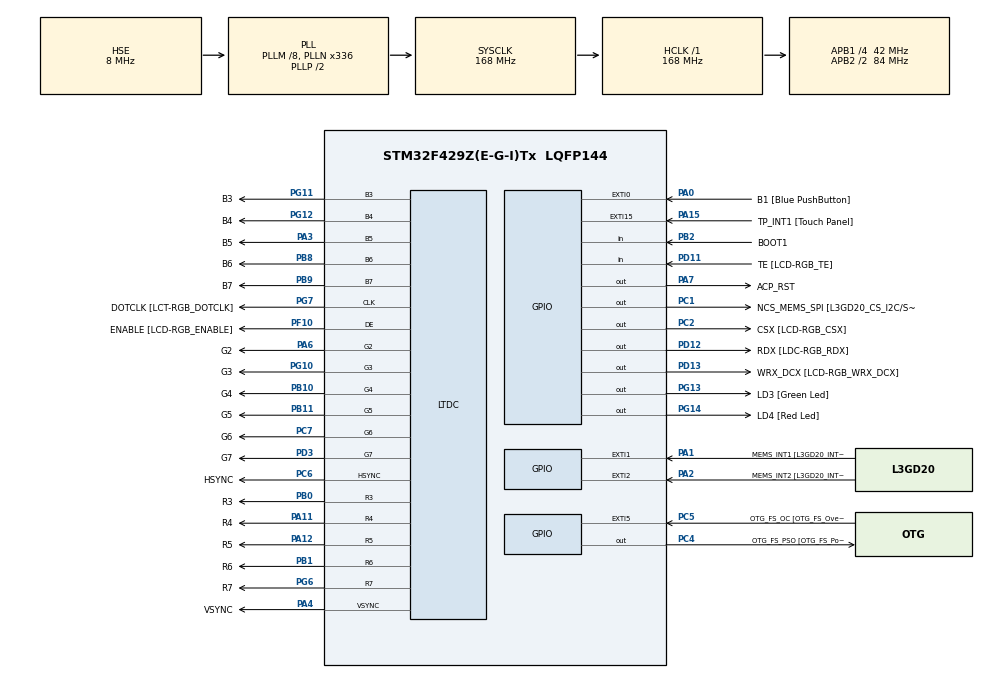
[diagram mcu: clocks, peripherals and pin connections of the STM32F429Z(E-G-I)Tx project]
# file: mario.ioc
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FREERTOS.Tasks01=defaultTask,0,128,StartDefaultTask
Mcu.Family=STM32F4
Mcu.Name=STM32F429Z(E-G-I)Tx
Mcu.Package=LQFP144
NVIC.PriorityGroup=NVIC_PRIORITYGROUP_4
NVIC.TIM6_DAC_IRQn=true\:5\:0\:false
PA0/WKUP.GPIO_Label=B1 [Blue PushButton]
PA0/WKUP.GPIO_ModeDefaultEXTI=GPIO_MODE_EVT_RISING
PA0/WKUP.GPIO_PuPd=GPIO_NOPULL
PA0/WKUP.Signal=GPXTI0
PA1.GPIO_Label=MEMS_INT1 [L3GD20_INT1]
PA1.GPIO_ModeDefaultEXTI=GPIO_MODE_EVT_RISING
PA1.GPIO_PuPd=GPIO_NOPULL
PA1.Signal=GPXTI1
PA11.GPIO_Label=R4
PA11.GPIO_Mode=GPIO_MODE_AF_PP
PA11.GPIO_PuPd=GPIO_NOPULL
PA11.GPIO_Speed=GPIO_SPEED_LOW
PA11.Mode=RGB565
PA11.Signal=LTDC_R4
PA12.GPIO_Label=R5
PA12.GPIO_Mode=GPIO_MODE_AF_PP
PA12.GPIO_PuPd=GPIO_NOPULL
PA12.GPIO_Speed=GPIO_SPEED_LOW
PA12.Mode=RGB565
PA12.Signal=LTDC_R5
PA13.GPIO_Label=SWDIO
PA13.Mode=Serial-Wire
PA13.Signal=SYS_JTMS-SWDIO
PA14.GPIO_Label=SWCLK
PA14.Mode=Serial-Wire
PA14.Signal=SYS_JTCK-SWCLK
PA15.GPIO_Label=TP_INT1 [Touch Panel]
PA15.GPIO_ModeDefaultEXTI=GPIO_MODE_EVT_RISING
PA15.GPIO_PuPd=GPIO_NOPULL
PA15.Signal=GPXTI15
PA2.GPIO_Label=MEMS_INT2 [L3GD20_INT2]
PA2.GPIO_ModeDefaultEXTI=GPIO_MODE_EVT_RISING
PA2.GPIO_PuPd=GPIO_NOPULL
PA2.Signal=GPXTI2
PA3.GPIO_Label=B5
PA3.GPIO_Mode=GPIO_MODE_AF_PP
PA3.GPIO_PuPd=GPIO_NOPULL
PA3.GPIO_Speed=GPIO_SPEED_LOW
PA3.Mode=RGB565
PA3.Signal=LTDC_B5
PA4.GPIO_Label=VSYNC
PA4.GPIO_Mode=GPIO_MODE_AF_PP
PA4.GPIO_PuPd=GPIO_NOPULL
PA4.GPIO_Speed=GPIO_SPEED_LOW
PA4.Mode=RGB565
PA4.Signal=LTDC_VSYNC
PA6.GPIO_Label=G2
PA6.GPIO_Mode=GPIO_MODE_AF_PP
PA6.GPIO_PuPd=GPIO_NOPULL
PA6.GPIO_Speed=GPIO_SPEED_LOW
PA6.Mode=RGB565
PA6.Signal=LTDC_G2
PA7.GPIO_Label=ACP_RST
PA7.GPIO_Mode=GPIO_MODE_OUTPUT_PP
PA7.GPIO_PuPd=GPIO_NOPULL
PA7.GPIO_Speed=GPIO_SPEED_LOW
PA7.Signal=GPIO_Output
PA8.GPIO_Label=I2C3_SCL [ACP/RF_SCL]
PA8.GPIO_Mode=GPIO_MODE_AF_OD
PA8.GPIO_PuPd=GPIO_NOPULL
PA8.GPIO_Speed=GPIO_SPEED_LOW
PA8.Signal=I2C3_SCL
PB0.GPIO_Label=R3
PB0.GPIO_Mode=GPIO_MODE_AF_PP
PB0.GPIO_PuPd=GPIO_NOPULL
PB0.GPIO_Speed=GPIO_SPEED_LOW
PB0.Mode=RGB565
PB0.Signal=LTDC_R3
PB1.GPIO_Label=R6
PB1.GPIO_Mode=GPIO_MODE_AF_PP
PB1.GPIO_PuPd=GPIO_NOPULL
PB1.GPIO_Speed=GPIO_SPEED_LOW
PB1.Mode=RGB565
PB1.Signal=LTDC_R6
PB10.GPIO_Label=G4
PB10.GPIO_Mode=GPIO_MODE_AF_PP
PB10.GPIO_PuPd=GPIO_NOPULL
PB10.GPIO_Speed=GPIO_SPEED_LOW
PB10.Mode=RGB565
PB10.Signal=LTDC_G4
PB11.GPIO_Label=G5
PB11.GPIO_Mode=GPIO_MODE_AF_PP
PB11.GPIO_PuPd=GPIO_NOPULL
PB11.GPIO_Speed=GPIO_SPEED_LOW
PB11.Mode=RGB565
PB11.Signal=LTDC_G5
PB12.GPIO_Label=OTG_FS_ID
PB12.GPIO_Mode=GPIO_MODE_AF_PP
PB12.GPIO_PuPd=GPIO_NOPULL
PB12.GPIO_Speed=GPIO_SPEED_LOW
PB12.Signal=USB_OTG_HS_ID
PB13.GPIO_Label=VBUS_FS
PB13.GPIO_Mode=GPIO_MODE_INPUT
PB13.GPIO_PuPd=GPIO_NOPULL
PB13.Signal=USB_OTG_HS_VBUS
PB14.GPIO_Label=OTG_FS_DM
PB14.GPIO_Mode=GPIO_MODE_AF_PP
PB14.GPIO_PuPd=GPIO_NOPULL
PB14.GPIO_Speed=GPIO_SPEED_LOW
PB14.Signal=USB_OTG_HS_DM
PB15.GPIO_Label=OTG_FS_DP
PB15.GPIO_Mode=GPIO_MODE_AF_PP
PB15.GPIO_PuPd=GPIO_NOPULL
PB15.GPIO_Speed=GPIO_SPEED_LOW
PB15.Signal=USB_OTG_HS_DP
PB2/BOOT1.GPIO_Label=BOOT1
PB2/BOOT1.GPIO_Mode=GPIO_MODE_INPUT
PB2/BOOT1.GPIO_PuPd=GPIO_NOPULL
PB2/BOOT1.Signal=GPIO_Input
PB5.GPIO_Label=SDCKE1
PB5.GPIO_Mode=GPIO_MODE_AF_PP
PB5.GPIO_PuPd=GPIO_NOPULL
PB5.GPIO_Speed=GPIO_SPEED_HIGH
PB5.Signal=FMC_SDCKE1
PB6.GPIO_Label=SDNE1 [SDRAM_CS]
PB6.GPIO_Mode=GPIO_MODE_AF_PP
PB6.GPIO_PuPd=GPIO_NOPULL
PB6.GPIO_Speed=GPIO_SPEED_HIGH
PB6.Signal=FMC_SDNE1
PB8.GPIO_Label=B6
PB8.GPIO_Mode=GPIO_MODE_AF_PP
PB8.GPIO_PuPd=GPIO_NOPULL
PB8.GPIO_Speed=GPIO_SPEED_LOW
PB8.Mode=RGB565
PB8.Signal=LTDC_B6
PB9.GPIO_Label=B7
PB9.GPIO_Mode=GPIO_MODE_AF_PP
PB9.GPIO_PuPd=GPIO_NOPULL
PB9.GPIO_Speed=GPIO_SPEED_LOW
PB9.Mode=RGB565
PB9.Signal=LTDC_B7
PC0.GPIO_Label=SDNWE
PC0.GPIO_Mode=GPIO_MODE_AF_PP
PC0.GPIO_PuPd=GPIO_NOPULL
PC0.GPIO_Speed=GPIO_SPEED_HIGH
PC0.Signal=FMC_SDNWE
PC1.GPIO_Label=NCS_MEMS_SPI [L3GD20_CS_I2C/SPI]
PC1.GPIO_Mode=GPIO_MODE_OUTPUT_PP
PC1.GPIO_PuPd=GPIO_NOPULL
PC1.GPIO_Speed=GPIO_SPEED_LOW
PC1.Signal=GPIO_Output
PC10.GPIO_Label=R2
PC10.GPIO_Mode=GPIO_MODE_AF_PP
PC10.GPIO_PuPd=GPIO_NOPULL
PC10.GPIO_Speed=GPIO_SPEED_LOW
PC10.Signal=LTDC_R2
PC14/OSC32_IN.GPIO_Label=PC14-OSC32_IN
PC14/OSC32_IN.Signal=RCC_OSC32_IN
PC15/OSC32_OUT.GPIO_Label=PC15-OSC32_OUT
PC15/OSC32_OUT.Signal=RCC_OSC32_OUT
PC2.GPIO_Label=CSX [LCD-RGB_CSX]
PC2.GPIO_Mode=GPIO_MODE_OUTPUT_PP
PC2.GPIO_PuPd=GPIO_NOPULL
PC2.GPIO_Speed=GPIO_SPEED_LOW
PC2.Signal=GPIO_Output
PC4.GPIO_Label=OTG_FS_PSO [OTG_FS_PowerSwitchOn]
PC4.GPIO_Mode=GPIO_MODE_OUTPUT_PP
PC4.GPIO_PuPd=GPIO_NOPULL
PC4.GPIO_Speed=GPIO_SPEED_LOW
PC4.Signal=GPIO_Output
PC5.GPIO_Label=OTG_FS_OC [OTG_FS_OverCurrent]
PC5.Signal=GPXTI5
PC6.GPIO_Label=HSYNC
PC6.GPIO_Mode=GPIO_MODE_AF_PP
PC6.GPIO_PuPd=GPIO_NOPULL
PC6.GPIO_Speed=GPIO_SPEED_LOW
PC6.Mode=RGB565
PC6.Signal=LTDC_HSYNC
PC7.GPIO_Label=G6
PC7.GPIO_Mode=GPIO_MODE_AF_PP
PC7.GPIO_PuPd=GPIO_NOPULL
PC7.GPIO_Speed=GPIO_SPEED_LOW
PC7.Mode=RGB565
PC7.Signal=LTDC_G6
PC9.GPIO_Label=I2C3_SDA [ACP/RF_SDA]
PC9.GPIO_Mode=GPIO_MODE_AF_OD
PC9.GPIO_PuPd=GPIO_NOPULL
PC9.GPIO_Speed=GPIO_SPEED_LOW
PC9.Signal=I2C3_SDA
PD0.GPIO_Label=D2
PD0.GPIO_Mode=GPIO_MODE_AF_PP
PD0.GPIO_PuPd=GPIO_NOPULL
PD0.GPIO_Speed=GPIO_SPEED_HIGH
PD0.Signal=FMC_D2_DA2
PD1.GPIO_Label=D3
PD1.GPIO_Mode=GPIO_MODE_AF_PP
PD1.GPIO_PuPd=GPIO_NOPULL
PD1.GPIO_Speed=GPIO_SPEED_HIGH
PD1.Signal=FMC_D3_DA3
PD10.GPIO_Label=D15
PD10.GPIO_Mode=GPIO_MODE_AF_PP
PD10.GPIO_PuPd=GPIO_NOPULL
PD10.GPIO_Speed=GPIO_SPEED_HIGH
PD10.Signal=FMC_D15_DA15
PD11.GPIO_Label=TE [LCD-RGB_TE]
PD11.GPIO_Mode=GPIO_MODE_INPUT
PD11.GPIO_PuPd=GPIO_NOPULL
PD11.Signal=GPIO_Input
PD12.GPIO_Label=RDX [LDC-RGB_RDX]
PD12.GPIO_Mode=GPIO_MODE_OUTPUT_PP
PD12.GPIO_PuPd=GPIO_NOPULL
PD12.GPIO_Speed=GPIO_SPEED_LOW
PD12.Signal=GPIO_Output
PD13.GPIO_Label=WRX_DCX [LCD-RGB_WRX_DCX]
PD13.GPIO_Mode=GPIO_MODE_OUTPUT_PP
PD13.GPIO_PuPd=GPIO_NOPULL
PD13.GPIO_Speed=GPIO_SPEED_LOW
PD13.Signal=GPIO_Output
PD14.GPIO_Label=D0
PD14.GPIO_Mode=GPIO_MODE_AF_PP
PD14.GPIO_PuPd=GPIO_NOPULL
PD14.GPIO_Speed=GPIO_SPEED_HIGH
PD14.Signal=FMC_D0_DA0
PD15.GPIO_Label=D1
PD15.GPIO_Mode=GPIO_MODE_AF_PP
PD15.GPIO_PuPd=GPIO_NOPULL
PD15.GPIO_Speed=GPIO_SPEED_HIGH
PD15.Signal=FMC_D1_DA1
PD3.GPIO_Label=G7
PD3.GPIO_Mode=GPIO_MODE_AF_PP
PD3.GPIO_PuPd=GPIO_NOPULL
PD3.GPIO_Speed=GPIO_SPEED_LOW
PD3.Mode=RGB565
PD3.Signal=LTDC_G7
PD6.GPIO_Label=B2
PD6.GPIO_Mode=GPIO_MODE_AF_PP
PD6.GPIO_PuPd=GPIO_NOPULL
PD6.GPIO_Speed=GPIO_SPEED_LOW
PD6.Signal=LTDC_B2
PD8.GPIO_Label=D13
PD8.GPIO_Mode=GPIO_MODE_AF_PP
PD8.GPIO_PuPd=GPIO_NOPULL
PD8.GPIO_Speed=GPIO_SPEED_HIGH
PD8.Signal=FMC_D13_DA13
PD9.GPIO_Label=D14
PD9.GPIO_Mode=GPIO_MODE_AF_PP
PD9.GPIO_PuPd=GPIO_NOPULL
PD9.GPIO_Speed=GPIO_SPEED_HIGH
PD9.Signal=FMC_D14_DA14
PE0.GPIO_Label=NBL0 [SDRAM_LDQM]
PE0.GPIO_Mode=GPIO_MODE_AF_PP
PE0.GPIO_PuPd=GPIO_NOPULL
PE0.GPIO_Speed=GPIO_SPEED_HIGH
PE0.Signal=FMC_NBL0
PE1.GPIO_Label=NBL1 [SDRAM_UDQM]
PE1.GPIO_Mode=GPIO_MODE_AF_PP
PE1.GPIO_PuPd=GPIO_NOPULL
PE1.GPIO_Speed=GPIO_SPEED_HIGH
PE1.Signal=FMC_NBL1
PE10.GPIO_Label=D7
PE10.GPIO_Mode=GPIO_MODE_AF_PP
PE10.GPIO_PuPd=GPIO_NOPULL
PE10.GPIO_Speed=GPIO_SPEED_HIGH
PE10.Signal=FMC_D7_DA7
PE11.GPIO_Label=D8
PE11.GPIO_Mode=GPIO_MODE_AF_PP
PE11.GPIO_PuPd=GPIO_NOPULL
PE11.GPIO_Speed=GPIO_SPEED_HIGH
PE11.Signal=FMC_D8_DA8
PE12.GPIO_Label=D9
PE12.GPIO_Mode=GPIO_MODE_AF_PP
PE12.GPIO_PuPd=GPIO_NOPULL
PE12.GPIO_Speed=GPIO_SPEED_HIGH
PE12.Signal=FMC_D9_DA9
PE13.GPIO_Label=D10
PE13.GPIO_Mode=GPIO_MODE_AF_PP
PE13.GPIO_PuPd=GPIO_NOPULL
PE13.GPIO_Speed=GPIO_SPEED_HIGH
PE13.Signal=FMC_D10_DA10
PE14.GPIO_Label=D11
PE14.GPIO_Mode=GPIO_MODE_AF_PP
PE14.GPIO_PuPd=GPIO_NOPULL
PE14.GPIO_Speed=GPIO_SPEED_HIGH
PE14.Signal=FMC_D11_DA11
PE15.GPIO_Label=D12
PE15.GPIO_Mode=GPIO_MODE_AF_PP
PE15.GPIO_PuPd=GPIO_NOPULL
PE15.GPIO_Speed=GPIO_SPEED_HIGH
PE15.Signal=FMC_D12_DA12
PE7.GPIO_Label=D4
PE7.GPIO_Mode=GPIO_MODE_AF_PP
PE7.GPIO_PuPd=GPIO_NOPULL
PE7.GPIO_Speed=GPIO_SPEED_HIGH
PE7.Signal=FMC_D4_DA4
PE8.GPIO_Label=D5
PE8.GPIO_Mode=GPIO_MODE_AF_PP
PE8.GPIO_PuPd=GPIO_NOPULL
PE8.GPIO_Speed=GPIO_SPEED_HIGH
PE8.Signal=FMC_D5_DA5
PE9.GPIO_Label=D6
PE9.GPIO_Mode=GPIO_MODE_AF_PP
PE9.GPIO_PuPd=GPIO_NOPULL
PE9.GPIO_Speed=GPIO_SPEED_HIGH
PE9.Signal=FMC_D6_DA6
PF0.GPIO_Label=A0
PF0.GPIO_Mode=GPIO_MODE_AF_PP
PF0.GPIO_PuPd=GPIO_NOPULL
PF0.GPIO_Speed=GPIO_SPEED_HIGH
PF0.Signal=FMC_A0
PF1.GPIO_Label=A1
PF1.GPIO_Mode=GPIO_MODE_AF_PP
PF1.GPIO_PuPd=GPIO_NOPULL
PF1.GPIO_Speed=GPIO_SPEED_HIGH
PF1.Signal=FMC_A1
PF10.GPIO_Label=ENABLE [LCD-RGB_ENABLE]
PF10.GPIO_Mode=GPIO_MODE_AF_PP
PF10.GPIO_PuPd=GPIO_NOPULL
PF10.GPIO_Speed=GPIO_SPEED_LOW
PF10.Mode=RGB565
PF10.Signal=LTDC_DE
PF11.GPIO_Label=SDNRAS
PF11.GPIO_Mode=GPIO_MODE_AF_PP
PF11.GPIO_PuPd=GPIO_NOPULL
PF11.GPIO_Speed=GPIO_SPEED_HIGH
PF11.Signal=FMC_SDNRAS
PF12.GPIO_Label=A6
PF12.GPIO_Mode=GPIO_MODE_AF_PP
PF12.GPIO_PuPd=GPIO_NOPULL
PF12.GPIO_Speed=GPIO_SPEED_HIGH
PF12.Signal=FMC_A6
PF13.GPIO_Label=A7
PF13.GPIO_Mode=GPIO_MODE_AF_PP
PF13.GPIO_PuPd=GPIO_NOPULL
PF13.GPIO_Speed=GPIO_SPEED_HIGH
PF13.Signal=FMC_A7
PF14.GPIO_Label=A8
PF14.GPIO_Mode=GPIO_MODE_AF_PP
PF14.GPIO_PuPd=GPIO_NOPULL
PF14.GPIO_Speed=GPIO_SPEED_HIGH
PF14.Signal=FMC_A8
PF15.GPIO_Label=A9
PF15.GPIO_Mode=GPIO_MODE_AF_PP
PF15.GPIO_PuPd=GPIO_NOPULL
PF15.GPIO_Speed=GPIO_SPEED_HIGH
PF15.Signal=FMC_A9
PF2.GPIO_Label=A2
PF2.GPIO_Mode=GPIO_MODE_AF_PP
PF2.GPIO_PuPd=GPIO_NOPULL
PF2.GPIO_Speed=GPIO_SPEED_HIGH
PF2.Signal=FMC_A2
PF3.GPIO_Label=A3
PF3.GPIO_Mode=GPIO_MODE_AF_PP
PF3.GPIO_PuPd=GPIO_NOPULL
PF3.GPIO_Speed=GPIO_SPEED_HIGH
PF3.Signal=FMC_A3
PF4.GPIO_Label=A4
PF4.GPIO_Mode=GPIO_MODE_AF_PP
PF4.GPIO_PuPd=GPIO_NOPULL
PF4.GPIO_Speed=GPIO_SPEED_HIGH
PF4.Signal=FMC_A4
PF5.GPIO_Label=A5
PF5.GPIO_Mode=GPIO_MODE_AF_PP
PF5.GPIO_PuPd=GPIO_NOPULL
PF5.GPIO_Speed=GPIO_SPEED_HIGH
PF5.Signal=FMC_A5
PF7.GPIO_Label=SPI5_SCK [L3GD20_SCL/SPC]
PF7.GPIO_Mode=GPIO_MODE_AF_PP
PF7.GPIO_PuPd=GPIO_NOPULL
PF7.GPIO_Speed=GPIO_SPEED_LOW
PF7.Signal=SPI5_SCK
PF8.GPIO_Label=SPI5_MISO [L3GD20_SDO]
PF8.GPIO_Mode=GPIO_MODE_AF_PP
PF8.GPIO_PuPd=GPIO_NOPULL
PF8.GPIO_Speed=GPIO_SPEED_LOW
PF8.Signal=SPI5_MISO
PF9.GPIO_Label=SPI5_MOSI [L3GD20_SDA/SDI/SDO]
PF9.GPIO_Mode=GPIO_MODE_AF_PP
PF9.GPIO_PuPd=GPIO_NOPULL
PF9.GPIO_Speed=GPIO_SPEED_LOW
PF9.Signal=SPI5_MOSI
PG0.GPIO_Label=A10
PG0.GPIO_Mode=GPIO_MODE_AF_PP
PG0.GPIO_PuPd=GPIO_NOPULL
PG0.GPIO_Speed=GPIO_SPEED_HIGH
PG0.Signal=FMC_A10
PG1.GPIO_Label=A11
PG1.GPIO_Mode=GPIO_MODE_AF_PP
PG1.GPIO_PuPd=GPIO_NOPULL
PG1.GPIO_Speed=GPIO_SPEED_HIGH
PG1.Signal=FMC_A11
PG10.GPIO_Label=G3
PG10.GPIO_Mode=GPIO_MODE_AF_PP
PG10.GPIO_PuPd=GPIO_NOPULL
PG10.GPIO_Speed=GPIO_SPEED_LOW
PG10.Mode=RGB565
PG10.Signal=LTDC_G3
PG11.GPIO_Label=B3
PG11.GPIO_Mode=GPIO_MODE_AF_PP
PG11.GPIO_PuPd=GPIO_NOPULL
PG11.GPIO_Speed=GPIO_SPEED_LOW
PG11.Mode=RGB565
PG11.Signal=LTDC_B3
PG12.GPIO_Label=B4
PG12.GPIO_Mode=GPIO_MODE_AF_PP
PG12.GPIO_PuPd=GPIO_NOPULL
PG12.GPIO_Speed=GPIO_SPEED_LOW
PG12.Mode=RGB565
PG12.Signal=LTDC_B4
PG13.GPIO_Label=LD3 [Green Led]
PG13.GPIO_Mode=GPIO_MODE_OUTPUT_PP
PG13.GPIO_PuPd=GPIO_NOPULL
PG13.GPIO_Speed=GPIO_SPEED_LOW
PG13.Signal=GPIO_Output
PG14.GPIO_Label=LD4 [Red Led]
PG14.GPIO_Mode=GPIO_MODE_OUTPUT_PP
PG14.GPIO_PuPd=GPIO_NOPULL
PG14.GPIO_Speed=GPIO_SPEED_LOW
PG14.Signal=GPIO_Output
PG15.GPIO_Label=SDNCAS
PG15.GPIO_Mode=GPIO_MODE_AF_PP
PG15.GPIO_PuPd=GPIO_NOPULL
PG15.GPIO_Speed=GPIO_SPEED_HIGH
PG15.Signal=FMC_SDNCAS
PG4.GPIO_Label=BA0
PG4.GPIO_Mode=GPIO_MODE_AF_PP
PG4.GPIO_PuPd=GPIO_NOPULL
PG4.GPIO_Speed=GPIO_SPEED_HIGH
PG4.Signal=FMC_A14_BA0
PG5.GPIO_Label=BA1
PG5.GPIO_Mode=GPIO_MODE_AF_PP
PG5.GPIO_PuPd=GPIO_NOPULL
PG5.GPIO_Speed=GPIO_SPEED_HIGH
PG5.Signal=FMC_A15_BA1
PG6.GPIO_Label=R7
PG6.GPIO_Mode=GPIO_MODE_AF_PP
PG6.GPIO_PuPd=GPIO_NOPULL
PG6.GPIO_Speed=GPIO_SPEED_LOW
PG6.Mode=RGB565
PG6.Signal=LTDC_R7
PG7.GPIO_Label=DOTCLK [LCT-RGB_DOTCLK]
PG7.GPIO_Mode=GPIO_MODE_AF_PP
PG7.GPIO_PuPd=GPIO_NOPULL
PG7.GPIO_Speed=GPIO_SPEED_LOW
PG7.Mode=RGB565
PG7.Signal=LTDC_CLK
PG8.GPIO_Label=SDCLK
PG8.GPIO_Mode=GPIO_MODE_AF_PP
PG8.GPIO_PuPd=GPIO_NOPULL
PG8.GPIO_Speed=GPIO_SPEED_HIGH
PG8.Signal=FMC_SDCLK
PH0/OSC_IN.GPIO_Label=PH0-OSC_IN
PH0/OSC_IN.Mode=HSE-External-Oscillator
PH0/OSC_IN.Signal=RCC_OSC_IN
PH1/OSC_OUT.GPIO_Label=PH1-OSC_OUT
PH1/OSC_OUT.Mode=HSE-External-Oscillator
PH1/OSC_OUT.Signal=RCC_OSC_OUT
ProjectManager.TargetToolchain=MDK-ARM V4
RCC.48MHZClocksFreq_Value=48000000
RCC.AHBFreq_Value=168000000
RCC.APB1CLKDivider=RCC_HCLK_DIV4
RCC.APB1Freq_Value=42000000
RCC.APB1TimFreq_Value=84000000
RCC.APB2CLKDivider=RCC_HCLK_DIV2
RCC.APB2Freq_Value=84000000
RCC.APB2TimFreq_Value=168000000
RCC.CortexFreq_Value=21000000
RCC.HCLKFreq_Value=168000000
RCC.HSE_VALUE=8000000
RCC.HSI_VALUE=16000000
RCC.LSE_VALUE=32768
RCC.PLLM=8
RCC.PLLN=336
RCC.PLLQ=7
RCC.PLLSAIN=432
RCC.PLLSource=RCC_PLLSOURCE_HSE
RCC.PLLSourceVirtual=RCC_PLLSOURCE_HSE
RCC.SYSCLKFreq_VALUE=168000000
RCC.SYSCLKSource=RCC_SYSCLKSOURCE_PLLCLK
RCC.VCOOutputFreq_Value=336000000
SH.FMC_A0.0=FMC_A0
SH.FMC_A1.0=FMC_A1
SH.FMC_A10.0=FMC_A10
SH.FMC_A11.0=FMC_A11
SH.FMC_A14_BA0.0=FMC_BA0
SH.FMC_A15_BA1.0=FMC_BA1
SH.FMC_A2.0=FMC_A2
SH.FMC_A3.0=FMC_A3
SH.FMC_A4.0=FMC_A4
SH.FMC_A5.0=FMC_A5
SH.FMC_A6.0=FMC_A6
SH.FMC_A7.0=FMC_A7
SH.FMC_A8.0=FMC_A8
SH.FMC_A9.0=FMC_A9
SH.FMC_D0_DA0.0=FMC_D0
SH.FMC_D10_DA10.0=FMC_D10
SH.FMC_D11_DA11.0=FMC_D11
SH.FMC_D12_DA12.0=FMC_D12
SH.FMC_D13_DA13.0=FMC_D13
SH.FMC_D14_DA14.0=FMC_D14
SH.FMC_D15_DA15.0=FMC_D15
SH.FMC_D1_DA1.0=FMC_D1
SH.FMC_D2_DA2.0=FMC_D2
SH.FMC_D3_DA3.0=FMC_D3
SH.FMC_D4_DA4.0=FMC_D4
SH.FMC_D5_DA5.0=FMC_D5
SH.FMC_D6_DA6.0=FMC_D6
SH.FMC_D7_DA7.0=FMC_D7
SH.FMC_D8_DA8.0=FMC_D8
SH.FMC_D9_DA9.0=FMC_D9
SH.FMC_NBL0.0=FMC_NBL0
SH.FMC_NBL1.0=FMC_NBL1
SH.FMC_SDCLK.0=FMC_SDCLK
SH.FMC_SDNCAS.0=FMC_SDNCAS
SH.FMC_SDNRAS.0=FMC_SDNRAS
SH.FMC_SDNWE.0=FMC_SDNWE
TIM6.Period=1000
VP_FREERTOS_VS_ENABLE.Mode=Enabled
VP_TIM6_VS_ClockSourceINT.Mode=Enable_Timer
VP_TIM7_VS_ClockSourceINT.Mode=Enable_Timer
VP_WWDG_VS_WWDG.Mode=WWDG_Activate

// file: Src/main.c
/**
  ******************************************************************************
  * File Name          : main.c
  * Date               : 19/05/2015 23:04:15
  * Description        : Main program body
  ******************************************************************************
  *
  * COPYRIGHT(c) 2015 STMicroelectronics
  *
  * Redistribution and use in source and binary forms, with or without modification,
  * are permitted provided that the following conditions are met:
  *   1. Redistributions of source code must retain the above copyright notice,
  *      this list of conditions and the following disclaimer.
  *   2. Redistributions in binary form must reproduce the above copyright notice,
  *      this list of conditions and the following disclaimer in the documentation
  *      and/or other materials provided with the distribution.
  *   3. Neither the name of STMicroelectronics nor the names of its contributors
  *      may be used to endorse or promote products derived from this software
  *      without specific prior written permission.
  *
  * THIS SOFTWARE IS PROVIDED BY THE COPYRIGHT HOLDERS AND CONTRIBUTORS "AS IS"
  * AND ANY EXPRESS OR IMPLIED WARRANTIES, INCLUDING, BUT NOT LIMITED TO, THE
  * IMPLIED WARRANTIES OF MERCHANTABILITY AND FITNESS FOR A PARTICULAR PURPOSE ARE
  * DISCLAIMED. IN NO EVENT SHALL THE COPYRIGHT HOLDER OR CONTRIBUTORS BE LIABLE
  * FOR ANY DIRECT, INDIRECT, INCIDENTAL, SPECIAL, EXEMPLARY, OR CONSEQUENTIAL
  * DAMAGES (INCLUDING, BUT NOT LIMITED TO, PROCUREMENT OF SUBSTITUTE GOODS OR
  * SERVICES; LOSS OF USE, DATA, OR PROFITS; OR BUSINESS INTERRUPTION) HOWEVER
  * CAUSED AND ON ANY THEORY OF LIABILITY, WHETHER IN CONTRACT, STRICT LIABILITY,
  * OR TORT (INCLUDING NEGLIGENCE OR OTHERWISE) ARISING IN ANY WAY OUT OF THE USE
  * OF THIS SOFTWARE, EVEN IF ADVISED OF THE POSSIBILITY OF SUCH DAMAGE.
  *
  ******************************************************************************
  */

#include "stm32f4xx_hal.h"
#include "cmsis_os.h"
#include "stm32f429i_discovery.h"
#include "..\Components\ili9341\ili9341.h"
#include "..\Components\stmpe811\stmpe811.h"
#include "stm32f429i_discovery_ts.h"
#include "stm32f429i_discovery_io.h"
#include "stm32f429i_discovery_lcd.h"
#include "stm32f429i_discovery_gyroscope.h"
#include "stm32f429i_discovery_sdram.h"
#include "arm_math.h"

typedef struct pos{
	int X;
	int Y;
} pos_t;

static unsigned short map[] = {
  1,1,1,1,1,1,1,1,1,1,1,1,1,1,1,1,1,1,1,
	1,0,0,0,0,0,0,0,0,1,0,0,0,0,0,0,0,0,1,
	1,0,1,1,0,1,1,1,0,1,0,1,1,1,0,1,1,0,1,
	1,0,0,0,0,0,0,0,0,0,0,0,0,0,0,0,0,0,1,
	1,0,1,1,0,1,0,1,1,1,1,1,0,1,0,1,1,0,1,
	1,0,0,0,0,1,0,0,0,1,0,0,0,1,0,0,0,0,1,
	1,1,1,1,0,1,1,1,0,1,0,1,1,1,0,1,1,1,1,
	0,0,0,1,0,1,0,0,0,0,0,0,0,1,0,1,0,0,0,
	1,1,1,1,0,1,0,1,1,1,1,1,0,1,0,1,1,1,1,
	1,1,1,1,0,0,0,1,0,0,0,1,0,0,0,1,1,1,1,
	1,1,1,1,0,1,0,1,1,1,1,1,0,1,0,1,1,1,1,
	0,0,0,1,0,1,0,0,0,0,0,0,0,1,0,1,0,0,0,
	1,1,1,1,0,1,0,1,1,1,1,1,0,1,0,1,1,1,1,
	1,0,0,0,0,0,0,0,0,1,0,0,0,0,0,0,0,0,1,
	1,0,1,1,0,1,1,1,0,1,0,1,1,1,0,1,1,0,1,
	1,0,0,1,0,0,0,0,0,0,0,0,0,0,0,1,0,0,1,
	1,1,0,1,0,1,0,1,1,1,1,1,0,1,0,1,0,1,1,
	1,0,0,0,0,1,0,0,0,1,0,0,0,1,0,0,0,0,1,
	1,0,1,1,1,1,1,1,0,1,0,1,1,1,1,1,1,0,1,
	1,0,0,0,0,0,0,0,0,0,0,0,0,0,0,0,0,0,1,
	1,1,1,1,1,1,1,1,1,1,1,1,1,1,1,1,1,1,1
};

static unsigned short food1_base[] = {
  0,0,0,0,0,0,0,0,0,0,0,0,0,0,0,0,0,0,0,
	0,1,1,1,1,1,1,1,1,0,1,1,1,1,1,1,1,1,0,
	0,1,0,0,1,0,0,0,1,0,1,0,0,0,1,0,0,1,0,
	0,1,1,1,1,1,1,1,1,1,1,1,1,1,1,1,1,1,0,
	0,1,0,0,1,0,1,0,0,0,0,0,1,0,1,0,0,1,0,
	0,1,1,1,1,0,1,1,1,0,1,1,1,0,1,1,1,1,0,
	0,0,0,0,1,0,0,0,1,0,1,0,0,0,1,0,0,0,0,
	0,0,0,0,1,0,1,1,1,0,1,1,1,0,1,0,0,0,0,
	0,0,0,0,1,0,1,0,0,0,0,0,1,0,1,0,0,0,0,
	0,0,0,0,1,1,1,0,0,0,0,0,1,1,1,0,0,0,0,
	0,0,0,0,1,0,1,0,0,0,0,0,1,0,1,0,0,0,0,
	0,0,0,0,1,0,1,1,1,1,1,1,1,0,1,0,0,0,0,
	0,0,0,0,1,0,1,0,0,0,0,0,1,0,1,0,0,0,0,
	0,1,1,1,1,1,1,1,1,0,1,1,1,1,1,1,1,1,0,
	0,1,0,0,1,0,0,0,1,0,1,0,0,0,1,0,0,1,0,
	0,1,1,0,1,1,1,1,1,1,1,1,1,1,1,0,1,1,0,
	0,0,1,0,1,0,1,0,0,0,0,0,1,0,1,0,1,0,0,
	0,1,1,1,1,0,1,1,1,0,1,1,1,0,1,1,1,1,0,
	0,1,0,0,0,0,0,0,1,0,1,0,0,0,0,0,0,1,0,
	0,1,1,1,1,1,1,1,1,0,1,1,1,1,1,1,1,1,0,
	0,0,0,0,0,0,0,0,0,0,0,0,0,0,0,0,0,0,0
};

static unsigned short food_base[] = {
  0,0,0,0,0,0,0,0,0,0,0,0,0,0,0,0,0,0,0,
	0,0,0,0,0,0,0,0,0,0,0,0,0,0,0,0,0,0,0,
	0,0,0,0,0,0,0,0,0,0,0,0,0,0,0,0,0,0,0,
	0,0,0,0,0,0,0,0,0,0,0,0,0,0,0,0,0,0,0,
	0,0,0,0,0,0,0,0,0,0,0,0,0,0,0,0,0,0,0,
	0,0,0,0,0,0,0,0,0,0,0,0,0,0,0,0,0,0,0,
	0,0,0,0,0,0,0,0,0,0,0,0,0,0,0,0,0,0,0,
	0,0,0,0,0,0,0,0,0,0,1,0,0,0,0,0,0,0,0,
	0,0,0,0,0,0,0,0,0,0,0,0,0,0,0,0,0,0,0,
	0,0,0,0,0,0,0,0,0,0,0,0,0,0,0,0,0,0,0,
	0,0,0,0,0,0,0,0,0,0,0,0,0,0,0,0,0,0,0,
	0,0,0,0,0,0,0,0,0,0,0,0,0,0,0,0,0,0,0,
	0,0,0,0,0,0,0,0,0,0,0,0,0,0,0,0,0,0,0,
	0,0,0,0,0,0,0,0,0,0,0,0,0,0,0,0,0,0,0,
	0,0,0,0,0,0,0,0,0,0,0,0,0,0,0,0,0,0,0,
	0,0,0,0,0,0,0,0,0,0,0,0,0,0,0,0,0,0,0,
	0,0,0,0,0,0,0,0,0,0,0,0,0,0,0,0,0,0,0,
	0,0,0,0,0,0,0,0,0,0,0,0,0,0,0,0,0,0,0,
	0,0,0,0,0,0,0,0,0,0,0,0,0,0,0,0,0,0,0,
	0,0,0,0,0,0,0,0,0,0,0,0,0,0,0,0,0,0,0,
	0,0,0,0,0,0,0,0,0,0,0,0,0,0,0,0,0,0,0
};

int temp_map[19*21]={
		0,0,0,0,0,0,0,0,0,0,0,0,0,0,0,0,0,0,0,
		0,0,0,0,0,0,0,0,0,0,0,0,0,0,0,0,0,0,0,
		0,0,0,0,0,0,0,0,0,0,0,0,0,0,0,0,0,0,0,
		0,0,0,0,0,0,0,0,0,0,0,0,0,0,0,0,0,0,0,
		0,0,0,0,0,0,0,0,0,0,0,0,0,0,0,0,0,0,0,
		0,0,0,0,0,0,0,0,0,0,0,0,0,0,0,0,0,0,0,
		0,0,0,0,0,0,0,0,0,0,0,0,0,0,0,0,0,0,0,
		0,0,0,0,0,0,0,0,0,0,0,0,0,0,0,0,0,0,0,
		0,0,0,0,0,0,0,0,0,0,0,0,0,0,0,0,0,0,0,
		0,0,0,0,0,0,0,0,0,0,0,0,0,0,0,0,0,0,0,
		0,0,0,0,0,0,0,0,0,0,0,0,0,0,0,0,0,0,0,
		0,0,0,0,0,0,0,0,0,0,0,0,0,0,0,0,0,0,0,
		0,0,0,0,0,0,0,0,0,0,0,0,0,0,0,0,0,0,0,
		0,0,0,0,0,0,0,0,0,0,0,0,0,0,0,0,0,0,0,
		0,0,0,0,0,0,0,0,0,0,0,0,0,0,0,0,0,0,0,
		0,0,0,0,0,0,0,0,0,0,0,0,0,0,0,0,0,0,0,
		0,0,0,0,0,0,0,0,0,0,0,0,0,0,0,0,0,0,0,
		0,0,0,0,0,0,0,0,0,0,0,0,0,0,0,0,0,0,0,
		0,0,0,0,0,0,0,0,0,0,0,0,0,0,0,0,0,0,0,
		0,0,0,0,0,0,0,0,0,0,0,0,0,0,0,0,0,0,0,
		0,0,0,0,0,0,0,0,0,0,0,0,0,0,0,0,0,0,0};

static unsigned short food[19*21];

LTDC_HandleTypeDef hltdc;
RNG_HandleTypeDef rng;
TIM_HandleTypeDef htim6;
TIM_HandleTypeDef htim7;
uint8_t status = 0;
WWDG_HandleTypeDef hwwdg;
short nextMove=0;
osThreadId defaultTaskHandle;
int points=0;
int totalFood=0;
unsigned short startXpos=9, startYpos=7;
pos_t playerPosition;
int lives=0;
int initialLives=3;
unsigned short startGhostXpos=9, startGhostYpos=19;
pos_t ghostPosition;
unsigned short SettingLowerTrigger=250, SettingUpperTrigger=70;
		short mode=1;
		short switchedMode=0;
		short controlType=1;
		TS_StateTypeDef  TS_State;
/* USER CODE BEGIN PV */
char text[15];
float Buffer[3];
float Xval=0;
float Yval=0;
float Zval = 0;
float angleX=0;
	float angleY=0;
	float angleZ=0;
	float X_BiasError,Y_BiasError,Z_BiasError;
/* USER CODE END PV */

void SystemClock_Config(void);
static void MX_GPIO_Init(void);
static void MX_LTDC_Init(void);
static void MX_TIM6_Init(void);
static void MX_TIM7_Init(void);
static void MX_WWDG_Init(void);
void StartDefaultTask(void const * argument);
void checkForTouch();
void updateMEMS();
void gameLoop();
void getControl_TS();
void getTSData();

/* USER CODE BEGIN 0 */
void blinkLed(){
	for(;;){
		BSP_LED_Toggle(LED3);
		osDelay(100);
	}
}

void Gyro_SimpleCalibration(float* GyroData)
{
  uint32_t BiasErrorSplNbr = 1000;

  int i = 0;
  X_BiasError = 0;
  Y_BiasError = 0;
  Z_BiasError = 0;
  for (i = 0; i < BiasErrorSplNbr; i++)
  {
		BSP_GYRO_GetXYZ(GyroData);
    X_BiasError += GyroData[0];
    Y_BiasError += GyroData[1];
    Z_BiasError += GyroData[2];
  }
  /* Set bias errors */
  X_BiasError /= BiasErrorSplNbr;
  Y_BiasError /= BiasErrorSplNbr;
  Z_BiasError /= BiasErrorSplNbr;

  /* Get offset value on X, Y and Z */
  GyroData[0] = X_BiasError;
  GyroData[1] = Y_BiasError;
  GyroData[2] = Z_BiasError;
}
/* USER CODE END 0 */

int main(void)
{

  /* MCU Configuration----------------------------------------------------------*/

  /* Reset of all peripherals, Initializes the Flash interface and the Systick. */
  HAL_Init();

  /* Configure the system clock */
  SystemClock_Config();

  /* Initialize all configured peripherals */
  MX_GPIO_Init();
  MX_LTDC_Init();
  MX_TIM6_Init();
  MX_TIM7_Init();
  MX_WWDG_Init();
	BSP_LED_Init(LED3);
	BSP_LCD_Init();
	__HAL_RCC_RNG_CLK_ENABLE();

	if (HAL_RNG_Init(&rng)==HAL_OK) BSP_LED_On(LED3);
  BSP_LCD_Clear(LCD_COLOR_BLACK);
	BSP_LCD_LayerDefaultInit(1, LCD_FRAME_BUFFER);
	/* Set LCD Foreground Layer  */
  BSP_LCD_SelectLayer(1);

  BSP_LCD_SetFont(&LCD_DEFAULT_FONT);

  /* Clear the LCD */

  status = BSP_TS_Init(BSP_LCD_GetXSize(), BSP_LCD_GetYSize());
	BSP_LCD_SetBackColor(LCD_COLOR_BLACK);
	BSP_LCD_SetTextColor(LCD_COLOR_CYAN);
	if (status==TS_OK){
		BSP_LCD_Clear(LCD_COLOR_BLACK);
		BSP_LCD_SetFont(&Font12);
		BSP_LCD_DisplayStringAt(180,310,(uint8_t*)"TS OK",LEFT_MODE);
		BSP_LCD_SetFont(&Font24);
	}
	else{
		BSP_LCD_Clear(LCD_COLOR_BLACK);
		BSP_LCD_SetFont(&Font12);
		BSP_LCD_DisplayStringAt(180,310,(uint8_t*)"TS NOT OK",LEFT_MODE);
		BSP_LCD_SetFont(&Font24);
	}

	if (BSP_GYRO_Init() != GYRO_OK)
  {
    BSP_LCD_SetTextColor(LCD_COLOR_RED);
		BSP_LCD_SetFont(&Font12);
    BSP_LCD_DisplayStringAt(100, BSP_LCD_GetYSize()- 80, (uint8_t*)"GYRO NOT OK", LEFT_MODE);
		BSP_LCD_SetFont(&Font24);
  }
	else{
		BSP_GYRO_Reset();
			osThreadDef(gyro,updateMEMS, osPriorityNormal,0,128);
			osThreadId gyroHandle = osThreadCreate(osThread(gyro),NULL);

			BSP_LCD_SetFont(&Font12);
			BSP_LCD_DisplayStringAt(100, 310, (uint8_t*)"GYRO OK", LEFT_MODE);
			BSP_LCD_SetFont(&Font24);
	}

	//Gyro_SimpleCalibration(Buffer);

  /* Create the thread(s) */
  /* definition and creation of defaultTask */
  osThreadDef(defaultTask, StartDefaultTask, osPriorityNormal, 0, 128);
  defaultTaskHandle = osThreadCreate(osThread(defaultTask), NULL);

//osThreadDef(blink, blinkLed, osPriorityNormal, 0, 128);
  //osThreadId blinkTaskHandle = osThreadCreate(osThread(blink), NULL);

	osThreadDef(touch,getControl_TS, osPriorityNormal,0,128);
	osThreadId touchHandle = osThreadCreate(osThread(touch),NULL);

	osThreadDef(pollTS,getTSData, osPriorityNormal,0,128);
	osThreadId pollTSHandle = osThreadCreate(osThread(pollTS),NULL);

	osThreadDef(game,gameLoop, osPriorityNormal,0,128);
	osThreadId gameHandle = osThreadCreate(osThread(game),NULL);

  /* Start scheduler */
  osKernelStart();

  /* We should never get here as control is now taken by the scheduler */

  /* Infinite loop */
  while (1)
  {

  }

}

/** System Clock Configuration
*/
void SystemClock_Config(void)
{

  RCC_OscInitTypeDef RCC_OscInitStruct;
  RCC_ClkInitTypeDef RCC_ClkInitStruct;
  RCC_PeriphCLKInitTypeDef PeriphClkInitStruct;

  __PWR_CLK_ENABLE();

  __HAL_PWR_VOLTAGESCALING_CONFIG(PWR_REGULATOR_VOLTAGE_SCALE1);

  RCC_OscInitStruct.OscillatorType = RCC_OSCILLATORTYPE_HSE;
  RCC_OscInitStruct.HSEState = RCC_HSE_ON;
  RCC_OscInitStruct.PLL.PLLState = RCC_PLL_ON;
  RCC_OscInitStruct.PLL.PLLSource = RCC_PLLSOURCE_HSE;
  RCC_OscInitStruct.PLL.PLLM = 8;
  RCC_OscInitStruct.PLL.PLLN = 336;
  RCC_OscInitStruct.PLL.PLLP = RCC_PLLP_DIV2;
  RCC_OscInitStruct.PLL.PLLQ = 7;
  HAL_RCC_OscConfig(&RCC_OscInitStruct);

  RCC_ClkInitStruct.ClockType = RCC_CLOCKTYPE_SYSCLK|RCC_CLOCKTYPE_PCLK1
                              |RCC_CLOCKTYPE_PCLK2;
  RCC_ClkInitStruct.SYSCLKSource = RCC_SYSCLKSOURCE_PLLCLK;
  RCC_ClkInitStruct.AHBCLKDivider = RCC_SYSCLK_DIV1;
  RCC_ClkInitStruct.APB1CLKDivider = RCC_HCLK_DIV4;
  RCC_ClkInitStruct.APB2CLKDivider = RCC_HCLK_DIV2;
  HAL_RCC_ClockConfig(&RCC_ClkInitStruct, FLASH_LATENCY_5);

  PeriphClkInitStruct.PeriphClockSelection = RCC_PERIPHCLK_LTDC;
  PeriphClkInitStruct.PLLSAI.PLLSAIN = 432;
  PeriphClkInitStruct.PLLSAI.PLLSAIR = 2;
  PeriphClkInitStruct.PLLSAIDivR = RCC_PLLSAIDIVR_2;
  HAL_RCCEx_PeriphCLKConfig(&PeriphClkInitStruct);

}

/* LTDC init function */
void MX_LTDC_Init(void)
{

  hltdc.Instance = LTDC;
  hltdc.Init.HSPolarity = LTDC_HSPOLARITY_AL;
  hltdc.Init.VSPolarity = LTDC_VSPOLARITY_AL;
  hltdc.Init.DEPolarity = LTDC_DEPOLARITY_AL;
  hltdc.Init.PCPolarity = LTDC_PCPOLARITY_IPC;
  hltdc.Init.HorizontalSync = 7;
  hltdc.Init.VerticalSync = 3;
  hltdc.Init.AccumulatedHBP = 14;
  hltdc.Init.AccumulatedVBP = 5;
  hltdc.Init.AccumulatedActiveW = 654;
  hltdc.Init.AccumulatedActiveH = 485;
  hltdc.Init.TotalWidth = 660;
  hltdc.Init.TotalHeigh = 487;
  hltdc.Init.Backcolor.Blue = 0;
  hltdc.Init.Backcolor.Green = 0;
  hltdc.Init.Backcolor.Red = 0;
  HAL_LTDC_Init(&hltdc);

}

/* TIM6 init function */
void MX_TIM6_Init(void)
{

  TIM_MasterConfigTypeDef sMasterConfig;

  htim6.Instance = TIM6;
  htim6.Init.Prescaler = 0;
  htim6.Init.CounterMode = TIM_COUNTERMODE_UP;
  htim6.Init.Period = 1000;
  HAL_TIM_Base_Init(&htim6);

  sMasterConfig.MasterOutputTrigger = TIM_TRGO_RESET;
  sMasterConfig.MasterSlaveMode = TIM_MASTERSLAVEMODE_DISABLE;
  HAL_TIMEx_MasterConfigSynchronization(&htim6, &sMasterConfig);

}

/* TIM7 init function */
void MX_TIM7_Init(void)
{

  TIM_MasterConfigTypeDef sMasterConfig;

  htim7.Instance = TIM7;
  htim7.Init.Prescaler = 0;
  htim7.Init.CounterMode = TIM_COUNTERMODE_UP;
  htim7.Init.Period = 0;
  HAL_TIM_Base_Init(&htim7);

  sMasterConfig.MasterOutputTrigger = TIM_TRGO_RESET;
  sMasterConfig.MasterSlaveMode = TIM_MASTERSLAVEMODE_DISABLE;
  HAL_TIMEx_MasterConfigSynchronization(&htim7, &sMasterConfig);

}

/* WWDG init function */
void MX_WWDG_Init(void)
{

  hwwdg.Instance = WWDG;
  hwwdg.Init.Prescaler = WWDG_PRESCALER_1;
  hwwdg.Init.Window = 64;
  hwwdg.Init.Counter = 64;
  HAL_WWDG_Init(&hwwdg);

}

/** Configure pins as
        * Analog
        * Input
        * Output
        * EVENT_OUT
        * EXTI
     PF0   ------> FMC_A0
     PF1   ------> FMC_A1
     PF2   ------> FMC_A2
     PF3   ------> FMC_A3
     PF4   ------> FMC_A4
     PF5   ------> FMC_A5
     PF7   ------> SPI5_SCK
     PF8   ------> SPI5_MISO
     PF9   ------> SPI5_MOSI
     PC0   ------> FMC_SDNWE
     PF11   ------> FMC_SDNRAS
     PF12   ------> FMC_A6
     PF13   ------> FMC_A7
     PF14   ------> FMC_A8
     PF15   ------> FMC_A9
     PG0   ------> FMC_A10
     PG1   ------> FMC_A11
     PE7   ------> FMC_D4_DA4
     PE8   ------> FMC_D5_DA5
     PE9   ------> FMC_D6_DA6
     PE10   ------> FMC_D7_DA7
     PE11   ------> FMC_D8_DA8
     PE12   ------> FMC_D9_DA9
     PE13   ------> FMC_D10_DA10
     PE14   ------> FMC_D11_DA11
     PE15   ------> FMC_D12_DA12
     PB12   ------> USB_OTG_HS_ID
     PB13   ------> USB_OTG_HS_VBUS
     PB14   ------> USB_OTG_HS_DM
     PB15   ------> USB_OTG_HS_DP
     PD8   ------> FMC_D13_DA13
     PD9   ------> FMC_D14_DA14
     PD10   ------> FMC_D15_DA15
     PD14   ------> FMC_D0_DA0
     PD15   ------> FMC_D1_DA1
     PG4   ------> FMC_A14_BA0
     PG5   ------> FMC_A15_BA1
     PG8   ------> FMC_SDCLK
     PC9   ------> I2C3_SDA
     PA8   ------> I2C3_SCL
     PD0   ------> FMC_D2_DA2
     PD1   ------> FMC_D3_DA3
     PG15   ------> FMC_SDNCAS
     PB5   ------> FMC_SDCKE1
     PB6   ------> FMC_SDNE1
     PE0   ------> FMC_NBL0
     PE1   ------> FMC_NBL1
*/
void MX_GPIO_Init(void)
{

  GPIO_InitTypeDef GPIO_InitStruct, GPIO_InitStr;

  /* GPIO Ports Clock Enable */
  __GPIOC_CLK_ENABLE();
  __GPIOF_CLK_ENABLE();
  __GPIOH_CLK_ENABLE();
  __GPIOA_CLK_ENABLE();
  __GPIOB_CLK_ENABLE();
  __GPIOG_CLK_ENABLE();
  __GPIOE_CLK_ENABLE();
  __GPIOD_CLK_ENABLE();

  /*Configure GPIO pins : PF0 PF1 PF2 PF3
                           PF4 PF5 PF11 PF12
                           PF13 PF14 PF15 */
  GPIO_InitStruct.Pin = GPIO_PIN_0|GPIO_PIN_1|GPIO_PIN_2|GPIO_PIN_3
                          |GPIO_PIN_4|GPIO_PIN_5|GPIO_PIN_11|GPIO_PIN_12
                          |GPIO_PIN_13|GPIO_PIN_14|GPIO_PIN_15;
  GPIO_InitStruct.Mode = GPIO_MODE_AF_PP;
  GPIO_InitStruct.Pull = GPIO_NOPULL;
  GPIO_InitStruct.Speed = GPIO_SPEED_HIGH;
  GPIO_InitStruct.Alternate = GPIO_AF12_FMC;
  HAL_GPIO_Init(GPIOF, &GPIO_InitStruct);

  /*Configure GPIO pins : PF7 PF8 PF9 */
  GPIO_InitStruct.Pin = GPIO_PIN_7|GPIO_PIN_8|GPIO_PIN_9;
  GPIO_InitStruct.Mode = GPIO_MODE_AF_PP;
  GPIO_InitStruct.Pull = GPIO_NOPULL;
  GPIO_InitStruct.Speed = GPIO_SPEED_LOW;
  GPIO_InitStruct.Alternate = GPIO_AF5_SPI5;
  HAL_GPIO_Init(GPIOF, &GPIO_InitStruct);

  /*Configure GPIO pin : PC0 */
  GPIO_InitStruct.Pin = GPIO_PIN_0;
  GPIO_InitStruct.Mode = GPIO_MODE_AF_PP;
  GPIO_InitStruct.Pull = GPIO_NOPULL;
  GPIO_InitStruct.Speed = GPIO_SPEED_HIGH;
  GPIO_InitStruct.Alternate = GPIO_AF12_FMC;
  HAL_GPIO_Init(GPIOC, &GPIO_InitStruct);

  /*Configure GPIO pins : PC1 PC2 PC4 */
  GPIO_InitStruct.Pin = GPIO_PIN_1|GPIO_PIN_2|GPIO_PIN_4;
  GPIO_InitStruct.Mode = GPIO_MODE_OUTPUT_PP;
  GPIO_InitStruct.Pull = GPIO_NOPULL;
  GPIO_InitStruct.Speed = GPIO_SPEED_LOW;
  HAL_GPIO_Init(GPIOC, &GPIO_InitStruct);

  /*Configure GPIO pins : PA0 PA1 PA2 PA15 */
  GPIO_InitStruct.Pin = GPIO_PIN_1|GPIO_PIN_2|GPIO_PIN_15;
  GPIO_InitStruct.Mode = GPIO_MODE_EVT_RISING;
  GPIO_InitStruct.Pull = GPIO_NOPULL;
  HAL_GPIO_Init(GPIOA, &GPIO_InitStruct);
	GPIO_InitStr.Pin = GPIO_PIN_0;
  GPIO_InitStr.Mode = GPIO_MODE_IT_RISING;
  GPIO_InitStr.Pull = GPIO_PULLDOWN;
  HAL_GPIO_Init(GPIOA, &GPIO_InitStr);
	HAL_NVIC_SetPriority(EXTI0_IRQn,0,0);
	HAL_NVIC_EnableIRQ(EXTI0_IRQn);

  /*Configure GPIO pin : PA7 */
  GPIO_InitStruct.Pin = GPIO_PIN_7;
  GPIO_InitStruct.Mode = GPIO_MODE_OUTPUT_PP;
  GPIO_InitStruct.Pull = GPIO_NOPULL;
  GPIO_InitStruct.Speed = GPIO_SPEED_LOW;
  HAL_GPIO_Init(GPIOA, &GPIO_InitStruct);

  /*Configure GPIO pin : PC5 */
  GPIO_InitStruct.Pin = GPIO_PIN_5;
  GPIO_InitStruct.Mode = GPIO_MODE_EVT_RISING;
  GPIO_InitStruct.Pull = GPIO_NOPULL;
  HAL_GPIO_Init(GPIOC, &GPIO_InitStruct);

  /*Configure GPIO pins : PB2 PB13 */
  GPIO_InitStruct.Pin = GPIO_PIN_2|GPIO_PIN_13;
  GPIO_InitStruct.Mode = GPIO_MODE_INPUT;
  GPIO_InitStruct.Pull = GPIO_NOPULL;
  HAL_GPIO_Init(GPIOB, &GPIO_InitStruct);

  /*Configure GPIO pins : PG0 PG1 PG4 PG5
                           PG8 PG15 */
  GPIO_InitStruct.Pin = GPIO_PIN_0|GPIO_PIN_1|GPIO_PIN_4|GPIO_PIN_5
                          |GPIO_PIN_8|GPIO_PIN_15;
  GPIO_InitStruct.Mode = GPIO_MODE_AF_PP;
  GPIO_InitStruct.Pull = GPIO_NOPULL;
  GPIO_InitStruct.Speed = GPIO_SPEED_HIGH;
  GPIO_InitStruct.Alternate = GPIO_AF12_FMC;
  HAL_GPIO_Init(GPIOG, &GPIO_InitStruct);

  /*Configure GPIO pins : PE7 PE8 PE9 PE10
                           PE11 PE12 PE13 PE14
                           PE15 PE0 PE1 */
  GPIO_InitStruct.Pin = GPIO_PIN_7|GPIO_PIN_8|GPIO_PIN_9|GPIO_PIN_10
                          |GPIO_PIN_11|GPIO_PIN_12|GPIO_PIN_13|GPIO_PIN_14
                          |GPIO_PIN_15|GPIO_PIN_0|GPIO_PIN_1;
  GPIO_InitStruct.Mode = GPIO_MODE_AF_PP;
  GPIO_InitStruct.Pull = GPIO_NOPULL;
  GPIO_InitStruct.Speed = GPIO_SPEED_HIGH;
  GPIO_InitStruct.Alternate = GPIO_AF12_FMC;
  HAL_GPIO_Init(GPIOE, &GPIO_InitStruct);

  /*Configure GPIO pins : PB12 PB14 PB15 */
  GPIO_InitStruct.Pin = GPIO_PIN_12|GPIO_PIN_14|GPIO_PIN_15;
  GPIO_InitStruct.Mode = GPIO_MODE_AF_PP;
  GPIO_InitStruct.Pull = GPIO_NOPULL;
  GPIO_InitStruct.Speed = GPIO_SPEED_LOW;
  GPIO_InitStruct.Alternate = GPIO_AF12_OTG_HS_FS;
  HAL_GPIO_Init(GPIOB, &GPIO_InitStruct);

  /*Configure GPIO pins : PD8 PD9 PD10 PD14
                           PD15 PD0 PD1 */
  GPIO_InitStruct.Pin = GPIO_PIN_8|GPIO_PIN_9|GPIO_PIN_10|GPIO_PIN_14
                          |GPIO_PIN_15|GPIO_PIN_0|GPIO_PIN_1;
  GPIO_InitStruct.Mode = GPIO_MODE_AF_PP;
  GPIO_InitStruct.Pull = GPIO_NOPULL;
  GPIO_InitStruct.Speed = GPIO_SPEED_HIGH;
  GPIO_InitStruct.Alternate = GPIO_AF12_FMC;
  HAL_GPIO_Init(GPIOD, &GPIO_InitStruct);

  /*Configure GPIO pin : PD11 */
  GPIO_InitStruct.Pin = GPIO_PIN_11;
  GPIO_InitStruct.Mode = GPIO_MODE_INPUT;
  GPIO_InitStruct.Pull = GPIO_NOPULL;
  HAL_GPIO_Init(GPIOD, &GPIO_InitStruct);

  /*Configure GPIO pins : PD12 PD13 */
  GPIO_InitStruct.Pin = GPIO_PIN_12|GPIO_PIN_13;
  GPIO_InitStruct.Mode = GPIO_MODE_OUTPUT_PP;
  GPIO_InitStruct.Pull = GPIO_NOPULL;
  GPIO_InitStruct.Speed = GPIO_SPEED_LOW;
  HAL_GPIO_Init(GPIOD, &GPIO_InitStruct);

  /*Configure GPIO pin : PC9 */
  GPIO_InitStruct.Pin = GPIO_PIN_9;
  GPIO_InitStruct.Mode = GPIO_MODE_AF_OD;
  GPIO_InitStruct.Pull = GPIO_PULLUP;
  GPIO_InitStruct.Speed = GPIO_SPEED_LOW;
  GPIO_InitStruct.Alternate = GPIO_AF4_I2C3;
  HAL_GPIO_Init(GPIOC, &GPIO_InitStruct);

  /*Configure GPIO pin : PA8 */
  GPIO_InitStruct.Pin = GPIO_PIN_8;
  GPIO_InitStruct.Mode = GPIO_MODE_AF_OD;
  GPIO_InitStruct.Pull = GPIO_PULLUP;
  GPIO_InitStruct.Speed = GPIO_SPEED_LOW;
  GPIO_InitStruct.Alternate = GPIO_AF4_I2C3;
  HAL_GPIO_Init(GPIOA, &GPIO_InitStruct);

  /*Configure GPIO pins : PG13 PG14 */
  GPIO_InitStruct.Pin = GPIO_PIN_13|GPIO_PIN_14;
  GPIO_InitStruct.Mode = GPIO_MODE_OUTPUT_PP;
  GPIO_InitStruct.Pull = GPIO_NOPULL;
  GPIO_InitStruct.Speed = GPIO_SPEED_LOW;
  HAL_GPIO_Init(GPIOG, &GPIO_InitStruct);

  /*Configure GPIO pins : PB5 PB6 */
  GPIO_InitStruct.Pin = GPIO_PIN_5|GPIO_PIN_6;
  GPIO_InitStruct.Mode = GPIO_MODE_AF_PP;
  GPIO_InitStruct.Pull = GPIO_NOPULL;
  GPIO_InitStruct.Speed = GPIO_SPEED_HIGH;
  GPIO_InitStruct.Alternate = GPIO_AF12_FMC;
  HAL_GPIO_Init(GPIOB, &GPIO_InitStruct);

}

/* StartDefaultTask function */
void StartDefaultTask(void const * argument)
{

  for(;;)
  {
    osDelay(1);
  }
}

static void WaitForPressedState(uint8_t Pressed)
{

  do
  {
    //BSP_TS_GetState(&TS_State);
    osDelay(10);
    if (TS_State.TouchDetected == Pressed)
    {
      uint16_t TimeStart = HAL_GetTick();
      do {
        //BSP_TS_GetState(&TS_State);
        osDelay(10);
        if (TS_State.TouchDetected != Pressed)
        {
          break;
        } else if ((HAL_GetTick() - 50) > TimeStart)
        {
          return;
        }
      } while (1);
    }
		if (switchedMode) return;
  } while (1);
}

void getTSData(){
	for(;;){
		BSP_TS_GetState(&TS_State);
		osDelay(10);
	}
}

void getControl_TS(){
	for(;;){
		if (controlType==1){
			if (TS_State.TouchDetected==1){
				if (TS_State.Y<SettingUpperTrigger) {nextMove=4;}
				else if (TS_State.Y>SettingLowerTrigger) {nextMove=3;}
				else if (TS_State.X<120) {nextMove=1;}
				else {nextMove=2;}
			}
		}
		osDelay(10);
	}
}

void updateMEMS(){
	for(;;){
		BSP_GYRO_GetXYZ(Buffer);
		Xval = (Buffer[0])-X_BiasError+1000;
    Yval = (Buffer[1])-Y_BiasError;
    Zval = (Buffer[2])-Z_BiasError;
		if (Xval>1000 || Xval<-1000)	angleX+=0.00875*0.01*Xval/8.65;
		if (Yval>1000 || Yval<-1000)	angleY+=0.00875*0.01*Yval/8.65;
		if (Zval>1000 || Zval<-1000)	angleZ+=0.00875*0.01*Zval/8.65;
		if (controlType==0){
			if (angleX<-13){nextMove=4;}
			if (angleX>13){nextMove=3;}
			if (angleY>13){nextMove=2;}
			if (angleY<-13){nextMove=1;}
		}
		osDelay(10);
	}
}

void drawBaseMap(){
	for(int i=0;i<21;i++){
		for(int j=0;j<19;j++){
			if (map[i*19+j]==1)	{BSP_LCD_SetTextColor(LCD_COLOR_DARKBLUE); BSP_LCD_FillRect((j*12)+5,i*12+30,12,12);}
			else if (food_base[i*19+j]==1) {BSP_LCD_SetTextColor(LCD_COLOR_RED); BSP_LCD_FillCircle((j*12)+10,i*12+36,2); }
		}
	}
}

void drawMap(){
	for(int i=0;i<21;i++){
		for(int j=0;j<19;j++){
			if (map[i*19+j]==1)	{BSP_LCD_SetTextColor(LCD_COLOR_DARKBLUE); BSP_LCD_FillRect((j*12)+5,i*12+30,12,12);}
			else if (food[i*19+j]==1) {BSP_LCD_SetTextColor(LCD_COLOR_RED); BSP_LCD_FillCircle((j*12)+10,i*12+36,2); }
		}
	}
}

void softResetGame(){
	//set initial position
	playerPosition.X = startXpos;
	playerPosition.Y = startYpos;
	ghostPosition.X = startGhostXpos;
	ghostPosition.Y = startGhostYpos;
	//draw map and player/ghost circles
	drawMap();
	BSP_LCD_SetTextColor(LCD_COLOR_YELLOW);
	BSP_LCD_FillCircle((playerPosition.X*12+10),(playerPosition.Y*12+36),5);
	BSP_LCD_SetTextColor(LCD_COLOR_CYAN);
	BSP_LCD_FillCircle((ghostPosition.X*12+10),(ghostPosition.Y*12+36),5);
	//display lives and points
	sprintf(text,"Lives: %d",lives);
	BSP_LCD_SetFont(&Font12);
	BSP_LCD_SetBackColor(LCD_COLOR_BLACK);
	BSP_LCD_SetTextColor(LCD_COLOR_YELLOW);
	BSP_LCD_DisplayStringAt(235,295,(uint8_t*)text,RIGHT_MODE);
	sprintf(text,"Points: %d",points);
	BSP_LCD_DisplayStringAt(10,10,(uint8_t*)text,LEFT_MODE);

}

void ResetGame(){
	for(int i=0;i<19*21;i++){
		food[i]=food_base[i];
	}
	//count the amount of food
	for(int i=0;i<19*21;i++){
		if (food[i]==1) totalFood++;
	}
	softResetGame();
}

void fullReset(){
	lives=initialLives;
	//verify that no food is on walls
	for(int i=0;i<19*21;i++){
		if (map[i]==1) food_base[i]=0;
	}
	//reset points
	points=0;
	ResetGame();
}

void mark(int* pathmap){
	int value=1;
	pathmap[ghostPosition.Y*19+ghostPosition.X]=1;
	int changes=1;
	while (changes>0){
		changes=0;
		for(int j=0;j<19;j++){
			for(int i=0;i<21;i++){
				if (pathmap[i*19+j]==value){
					if (map[i*19+j-1]==0 && pathmap[i*19+j-1]==0) {pathmap[i*19+j-1]=value+1; changes++;}
					if (map[i*19+j+1]==0 && pathmap[i*19+j+1]==0) {pathmap[i*19+j+1]=value+1; changes++;}
					if (map[i*19+j-19]==0 && pathmap[i*19+j-19]==0) {pathmap[i*19+j-19]=value+1; changes++;}
					if (map[i*19+j+19]==0 && pathmap[i*19+j+19]==0) {pathmap[i*19+j+19]=value+1; changes++;}
				}
			}
		}
		value++;
	}
}

int proceedMovements(){
	unsigned short nextGhostMove=0;
	unsigned short nextPlayerMove=0;

	//pathfinding
	//prepare data storage for wave algorithm
	for(int j=0;j<19;j++){
		for(int i=0;i<21;i++){
			temp_map[i*19+j]=0;
		}
	}
	//run wave algorithm
	mark(temp_map);
	//walk from destination to source to get next step
	short nextX=playerPosition.X,nextY=playerPosition.Y;
	for(int i=temp_map[playerPosition.Y*19+playerPosition.X];i>2;i--){
		if (temp_map[nextY*19+nextX-1]==i-1) {nextX--;}
		if (temp_map[nextY*19+nextX+1]==i-1) {nextX++;}
		if (temp_map[nextY*19+nextX-19]==i-1) {nextY--;}
		if (temp_map[nextY*19+nextX+19]==i-1) {nextY++;}
	}
	//get the "code" of next step
	if (nextX<ghostPosition.X) {nextGhostMove=1;}
	if (nextX>ghostPosition.X) {nextGhostMove=2;}
	if (nextY<ghostPosition.Y) {nextGhostMove=3;}
	if (nextY>ghostPosition.Y) {nextGhostMove=4;}
	if ((temp_map[nextY*19+nextX-1]+temp_map[nextY*19+nextX+1]+temp_map[nextY*19+nextX-19]+temp_map[nextY*19+nextX+19])==0) {nextGhostMove=0;}
	//determine, if player's next move is possible
	if (nextMove==1 && map[playerPosition.Y*19+playerPosition.X-1]==0 && playerPosition.X-1>=0){
		nextPlayerMove=1;
	}
	else if (nextMove==2 && map[playerPosition.Y*19+playerPosition.X+1]==0 && playerPosition.X+1<=19){
		nextPlayerMove=2;
	}
	else if (nextMove==3 && map[(playerPosition.Y+1)*19+playerPosition.X]==0 && playerPosition.Y+1<=21){
		nextPlayerMove=3;
	}
	else if (nextMove==4 && map[(playerPosition.Y-1)*19+playerPosition.X]==0 && playerPosition.Y-1>=0){
		nextPlayerMove=4;
	}

	//determine, if ghost and player will collide
	short drawFrames;
	if ((ghostPosition.X==playerPosition.X-1 && ghostPosition.Y==playerPosition.Y && (nextPlayerMove==1 || nextPlayerMove==0) && nextGhostMove==2)||(ghostPosition.X==playerPosition.X+1 && ghostPosition.Y==playerPosition.Y && (nextPlayerMove==2 || nextPlayerMove==0) && nextGhostMove==1)||
		(ghostPosition.Y==playerPosition.Y+1 &&  ghostPosition.X==playerPosition.X && (nextPlayerMove==3 || nextPlayerMove==0) && nextGhostMove==3)||(ghostPosition.Y==playerPosition.Y-1 && ghostPosition.X==playerPosition.X && (nextPlayerMove==4 || nextPlayerMove==0) && nextGhostMove==4)|| (ghostPosition.Y==playerPosition.Y && ghostPosition.X==playerPosition.X)){
		drawFrames=6;
	}
	else drawFrames=12;

	//determine, if there is a food piece in player's destination and remove it, if player eats it - remove from grid and award points
	if (nextPlayerMove==1 && food[playerPosition.Y*19+playerPosition.X-1]==1 && drawFrames==12){
		food[playerPosition.Y*19+playerPosition.X-1]=0;
		points+=10;
		totalFood--;
	}
	else if (nextPlayerMove==2 && food[playerPosition.Y*19+playerPosition.X+1]==1 && drawFrames==12){
		food[playerPosition.Y*19+playerPosition.X+1]=0;
		points+=10;
		totalFood--;
	}
	else if (nextPlayerMove==3 && food[(playerPosition.Y+1)*19+playerPosition.X]==1 && drawFrames==12){
		food[(playerPosition.Y+1)*19+playerPosition.X]=0;
		points+=10;
		totalFood--;
	}
	else if (nextPlayerMove==4 && food[(playerPosition.Y-1)*19+playerPosition.X]==1 && drawFrames==12){
		food[(playerPosition.Y-1)*19+playerPosition.X]=0;
		points+=10;
		totalFood--;
	}

	//draw
	for(int i=1;i<=drawFrames;i++){
		BSP_LCD_SetTextColor(LCD_COLOR_BLACK);
		switch (nextPlayerMove){
			case 1:BSP_LCD_FillCircle((playerPosition.X*12+10)-(i-1),playerPosition.Y*12+36,5); break;
			case 2:BSP_LCD_FillCircle((playerPosition.X*12+10)+(i-1),playerPosition.Y*12+36,5); break;
			case 3:BSP_LCD_FillCircle((playerPosition.X*12+10),(playerPosition.Y*12+36)+(i-1),5); break;
			case 4:BSP_LCD_FillCircle((playerPosition.X*12+10),(playerPosition.Y*12+36)-(i-1),5); break;
			default:break;
		}
		BSP_LCD_SetTextColor(LCD_COLOR_YELLOW);
		switch (nextPlayerMove){
			case 1:BSP_LCD_FillCircle((playerPosition.X*12+10)-(i),playerPosition.Y*12+36,5); break;
			case 2:BSP_LCD_FillCircle((playerPosition.X*12+10)+(i),playerPosition.Y*12+36,5); break;
			case 3:BSP_LCD_FillCircle((playerPosition.X*12+10),(playerPosition.Y*12+36)+(i),5); break;
			case 4:BSP_LCD_FillCircle((playerPosition.X*12+10),(playerPosition.Y*12+36)-(i),5); break;
			default:break;
		}
		BSP_LCD_SetTextColor(LCD_COLOR_BLACK);
		switch (nextGhostMove){
			case 1:BSP_LCD_FillCircle((ghostPosition.X*12+10)-(i-1),ghostPosition.Y*12+36,5); break;
			case 2:BSP_LCD_FillCircle((ghostPosition.X*12+10)+(i-1),ghostPosition.Y*12+36,5); break;
			case 3:BSP_LCD_FillCircle((ghostPosition.X*12+10),(ghostPosition.Y*12+36)-(i-1),5); break;
			case 4:BSP_LCD_FillCircle((ghostPosition.X*12+10),(ghostPosition.Y*12+36)+(i-1),5); break;
			default:break;
		}
		BSP_LCD_SetTextColor(LCD_COLOR_CYAN);
		switch (nextGhostMove){
			case 1:BSP_LCD_FillCircle((ghostPosition.X*12+10)-(i),ghostPosition.Y*12+36,5); break;
			case 2:BSP_LCD_FillCircle((ghostPosition.X*12+10)+(i),ghostPosition.Y*12+36,5); break;
			case 3:BSP_LCD_FillCircle((ghostPosition.X*12+10),(ghostPosition.Y*12+36)-(i),5); break;
			case 4:BSP_LCD_FillCircle((ghostPosition.X*12+10),(ghostPosition.Y*12+36)+(i),5); break;
			default:break;
		}
		osDelay(20);
	}
	for(int i=12;i>=drawFrames;i--){
		osDelay(20);
	}

	//if ghost catches player, we need to remove their models from screen
	if (drawFrames==6) {
		BSP_LCD_SetTextColor(LCD_COLOR_BLACK);
		BSP_LCD_FillCircle((playerPosition.X*12+10),playerPosition.Y*12+36,5);
		switch (nextPlayerMove){
			case 1:BSP_LCD_FillCircle((playerPosition.X*12+10)-6,playerPosition.Y*12+36,5); break;
			case 2:BSP_LCD_FillCircle((playerPosition.X*12+10)+6,playerPosition.Y*12+36,5); break;
			case 3:BSP_LCD_FillCircle((playerPosition.X*12+10),(playerPosition.Y*12+36)+6,5); break;
			case 4:BSP_LCD_FillCircle((playerPosition.X*12+10),(playerPosition.Y*12+36)-6,5); break;
			default:break;
		}
		switch (nextGhostMove){
			case 1:BSP_LCD_FillCircle((ghostPosition.X*12+10)-6,ghostPosition.Y*12+36,5); break;
			case 2:BSP_LCD_FillCircle((ghostPosition.X*12+10)+6,ghostPosition.Y*12+36,5); break;
			case 3:BSP_LCD_FillCircle((ghostPosition.X*12+10),(ghostPosition.Y*12+36)-6,5); break;
			case 4:BSP_LCD_FillCircle((ghostPosition.X*12+10),(ghostPosition.Y*12+36)+6,5); break;
			default:break;
		}
	}
	//update position
	switch (nextPlayerMove){
			case 1:playerPosition.X--; break;
			case 2:playerPosition.X++; break;
			case 3:playerPosition.Y++; break;
			case 4:playerPosition.Y--; break;
			default:break;
		}
	switch (nextGhostMove){
			case 1:ghostPosition.X--; break;
			case 2:ghostPosition.X++; break;
			case 3:ghostPosition.Y--; break;
			case 4:ghostPosition.Y++; break;
			default:break;
		}
	//return 1 if everything is ok, 0 if collision occured
	if (drawFrames==6) return 0;
	else return 1;
}

void mapEditor(){
	BSP_LCD_Clear(LCD_COLOR_BLACK);
	BSP_LCD_SetTextColor(LCD_COLOR_YELLOW);
	BSP_LCD_DrawRect(214,0,25,25);
	BSP_LCD_DrawLine(220,5,235,20);
	BSP_LCD_DrawLine(235,5,220,20);
	BSP_LCD_SetTextColor(LCD_COLOR_BLUE);
	BSP_LCD_FillRect(10,300,12,12);
	BSP_LCD_SetTextColor(LCD_COLOR_DARKGRAY);
	BSP_LCD_DrawRect(28,300,12,12);
	BSP_LCD_SetTextColor(LCD_COLOR_RED);
	BSP_LCD_FillCircle(51,306,2);
	BSP_LCD_SetTextColor(LCD_COLOR_YELLOW);
	BSP_LCD_FillCircle(68,306,5);
	BSP_LCD_SetTextColor(LCD_COLOR_CYAN);
	BSP_LCD_FillCircle(85,306,5);
	BSP_LCD_SetTextColor(LCD_COLOR_YELLOW);
	BSP_LCD_DrawRect(4,29,229,253);
	BSP_LCD_FillCircle(startXpos*12+11, startYpos*12+36,5);
	BSP_LCD_SetTextColor(LCD_COLOR_CYAN);
	BSP_LCD_FillCircle(startGhostXpos*12+11, startGhostYpos*12+36,5);
	int currentInstrument=0;
	int changed=0;
	int touchX=0;
	int touchY=0;
	for(;;){
		BSP_LCD_SetTextColor(LCD_COLOR_YELLOW);
		BSP_LCD_FillCircle(startXpos*12+11, startYpos*12+36,5);
		BSP_LCD_SetTextColor(LCD_COLOR_CYAN);
		BSP_LCD_FillCircle(startGhostXpos*12+11, startGhostYpos*12+36,5);
		drawBaseMap();
		//close button
		if (TS_State.TouchDetected==1 && TS_State.X>214 && TS_State.X<240 && TS_State.Y>0 && TS_State.Y<25) {
			fullReset();
			BSP_LCD_Clear(LCD_COLOR_BLACK);
			BSP_LCD_SetTextColor(LCD_COLOR_BLUE);
			BSP_LCD_FillRect(40,130,160,90);
			BSP_LCD_SetTextColor(LCD_COLOR_YELLOW);
			BSP_LCD_SetBackColor(LCD_COLOR_BLUE);
			BSP_LCD_SetFont(&Font20);
			BSP_LCD_DisplayStringAt(75,135,(uint8_t*)"Paused",LEFT_MODE);
			BSP_LCD_DrawRect(70,160,100,20);
			BSP_LCD_SetFont(&Font16);
			BSP_LCD_DisplayStringAt(75,162,(uint8_t*)"Settings",LEFT_MODE);
			BSP_LCD_DrawRect(70,185,100,20);
			BSP_LCD_SetFont(&Font16);
			BSP_LCD_DisplayStringAt(85,187,(uint8_t*)"Editor",LEFT_MODE);
			return;
		}
		if (TS_State.TouchDetected==1 && TS_State.X>10 && TS_State.X<22 && TS_State.Y>300 && TS_State.Y<312) {
			changed=currentInstrument; currentInstrument=1;
		}
		if (TS_State.TouchDetected==1 && TS_State.X>28 && TS_State.X<40 && TS_State.Y>300 && TS_State.Y<312) {
			changed=currentInstrument; currentInstrument=2;
		}
		if (TS_State.TouchDetected==1 && TS_State.X>45 && TS_State.X<57 && TS_State.Y>300 && TS_State.Y<312) {
			changed=currentInstrument; currentInstrument=3;
		}
		if (TS_State.TouchDetected==1 && TS_State.X>62 && TS_State.X<74 && TS_State.Y>300 && TS_State.Y<312) {
			changed=currentInstrument; currentInstrument=4;
		}
		if (TS_State.TouchDetected==1 && TS_State.X>79 && TS_State.X<91 && TS_State.Y>300 && TS_State.Y<312) {
			changed=currentInstrument; currentInstrument=5;
		}
		if (changed){
			BSP_LCD_SetTextColor(LCD_COLOR_BLACK);
			switch (changed){
				case 1:BSP_LCD_DrawRect(9,299,14,14); break;
				case 2:BSP_LCD_DrawRect(27,299,14,14); break;
				case 3:BSP_LCD_DrawRect(44,299,14,14); break;
				case 4:BSP_LCD_DrawRect(61,299,14,14); break;
				case 5:BSP_LCD_DrawRect(78,299,14,14); break;
			}
			changed=0;
			BSP_LCD_SetTextColor(LCD_COLOR_YELLOW);
			switch (currentInstrument){
				case 1:BSP_LCD_DrawRect(9,299,14,14); break;
				case 2:BSP_LCD_DrawRect(27,299,14,14); break;
				case 3:BSP_LCD_DrawRect(44,299,14,14); break;
				case 4:BSP_LCD_DrawRect(61,299,14,14); break;
				case 5:BSP_LCD_DrawRect(78,299,14,14); break;
			}
		}

		if (TS_State.TouchDetected==1 && TS_State.X>5 && TS_State.X<234 && TS_State.Y>30 && TS_State.Y<282) {
			touchX=(TS_State.X-5)/12;
			touchY=(TS_State.Y-30)/12;
			BSP_LCD_SetTextColor(LCD_COLOR_BLACK);
			BSP_LCD_FillRect((touchX*12)+5,touchY*12+30,12,12);
			if (currentInstrument==1) {
				map[touchY*19+touchX]=1;
				food_base[touchY*19+touchX]=0;
			}
			if (currentInstrument==2) {
				map[touchY*19+touchX]=0;
				food_base[touchY*19+touchX]=0;
			}
			if (currentInstrument==3) {
				food_base[touchY*19+touchX]=1;
				map[touchY*19+touchX]=0;
			}
			if (currentInstrument==4) {
				food_base[touchY*19+touchX]=0;
				map[touchY*19+touchX]=0;
				BSP_LCD_FillRect((startXpos*12)+5,startYpos*12+30,12,12);
				startXpos=touchX;
				startYpos=touchY;
			}
			if (currentInstrument==5) {
				food_base[touchY*19+touchX]=0;
				map[touchY*19+touchX]=0;
				BSP_LCD_FillRect((startGhostXpos*12)+5,startGhostYpos*12+30,12,12);
				startGhostXpos=touchX;
				startGhostYpos=touchY;
			}
		}
		osDelay(40);
	}
}

void manageSettings(){
	BSP_LCD_Clear(LCD_COLOR_BLACK);
	//header
	BSP_LCD_SetTextColor(LCD_COLOR_BLUE);
	BSP_LCD_FillRect(0,0,240,25);
	BSP_LCD_SetFont(&Font20);
	BSP_LCD_SetTextColor(LCD_COLOR_YELLOW);
	BSP_LCD_DisplayStringAt(70,2,(uint8_t*)"Settings",LEFT_MODE);
	//cross
	BSP_LCD_DrawRect(214,0,25,25);
	BSP_LCD_DrawLine(220,5,235,20);
	BSP_LCD_DrawLine(235,5,220,20);
	//+/- buttons
	BSP_LCD_SetBackColor(LCD_COLOR_BLACK);
	BSP_LCD_SetFont(&Font24);
	BSP_LCD_DisplayChar(150,80,(uint8_t)'+');
	BSP_LCD_DisplayChar(180,80,(uint8_t)'-');
	BSP_LCD_DrawRect(148,80,20,20);
	BSP_LCD_DrawRect(178,80,20,20);
	BSP_LCD_DisplayChar(150,110,(uint8_t)'+');
	BSP_LCD_DisplayChar(180,110,(uint8_t)'-');
	BSP_LCD_DrawRect(148,110,20,20);
	BSP_LCD_DrawRect(178,110,20,20);
	//frames of switches
	BSP_LCD_DrawRect(30,150,80,25);
	BSP_LCD_DrawRect(130,150,80,25);

	//draw control type buttons depending on control type chosen
	if (controlType==0){

		BSP_LCD_SetTextColor(LCD_COLOR_RED);
		BSP_LCD_FillRect(31,151,79,24);
		BSP_LCD_SetTextColor(LCD_COLOR_BLACK);
		BSP_LCD_FillRect(131,151,79,24);
		BSP_LCD_SetTextColor(LCD_COLOR_YELLOW);
		BSP_LCD_SetFont(&Font20);
		BSP_LCD_DisplayStringAt(153,153,(uint8_t*)"TS",LEFT_MODE);
		BSP_LCD_SetBackColor(LCD_COLOR_RED);
		BSP_LCD_DisplayStringAt(43,153,(uint8_t*)"Gyro",LEFT_MODE);
		BSP_LCD_SetBackColor(LCD_COLOR_BLACK);
	}
	else{
		BSP_LCD_SetTextColor(LCD_COLOR_RED);
		BSP_LCD_FillRect(131,151,79,24);
		BSP_LCD_SetTextColor(LCD_COLOR_BLACK);
		BSP_LCD_FillRect(31,151,79,24);
		BSP_LCD_SetTextColor(LCD_COLOR_YELLOW);
		BSP_LCD_SetFont(&Font20);
		BSP_LCD_DisplayStringAt(43,153,(uint8_t*)"Gyro",LEFT_MODE);
		BSP_LCD_SetBackColor(LCD_COLOR_RED);
		BSP_LCD_DisplayStringAt(153,153,(uint8_t*)"TS",LEFT_MODE);
		BSP_LCD_SetBackColor(LCD_COLOR_BLACK);
	}

	//zone marks
	BSP_LCD_SetTextColor(LCD_COLOR_RED);
	BSP_LCD_DrawLine(220,SettingUpperTrigger,239,SettingUpperTrigger);
	BSP_LCD_SetTextColor(LCD_COLOR_CYAN);
	BSP_LCD_DrawLine(220,SettingLowerTrigger,239,SettingLowerTrigger);
	BSP_LCD_SetFont(&Font24);
	char buf[6];
	sprintf(buf,"   %d",SettingUpperTrigger);
	BSP_LCD_DisplayStringAt(140,80,(uint8_t*)buf,RIGHT_MODE);
	sprintf(buf,"   %d",SettingLowerTrigger);
	BSP_LCD_DisplayStringAt(140,110,(uint8_t*)buf,RIGHT_MODE);
	for(;;){
		//close button
		if (TS_State.TouchDetected==1 && TS_State.X>214 && TS_State.X<240 && TS_State.Y>0 && TS_State.Y<25) {
			BSP_LCD_Clear(LCD_COLOR_BLACK);
			BSP_LCD_SetTextColor(LCD_COLOR_BLUE);
			BSP_LCD_FillRect(40,130,160,90);
			BSP_LCD_SetTextColor(LCD_COLOR_YELLOW);
			BSP_LCD_SetBackColor(LCD_COLOR_BLUE);
			BSP_LCD_SetFont(&Font20);
			BSP_LCD_DisplayStringAt(75,135,(uint8_t*)"Paused",LEFT_MODE);
			BSP_LCD_DrawRect(70,160,100,20);
			BSP_LCD_SetFont(&Font16);
			BSP_LCD_DisplayStringAt(75,162,(uint8_t*)"Settings",LEFT_MODE);
			BSP_LCD_DrawRect(70,185,100,20);
			BSP_LCD_SetFont(&Font16);
			BSP_LCD_DisplayStringAt(85,187,(uint8_t*)"Editor",LEFT_MODE);
			return;
		}

		//upper trigger +
		if (TS_State.TouchDetected==1 && TS_State.X>148 && TS_State.X<168 && TS_State.Y>80 && TS_State.Y<100) {
			if (SettingUpperTrigger<SettingLowerTrigger-20){
				SettingUpperTrigger++;
				sprintf(buf,"   %d",SettingUpperTrigger);
				BSP_LCD_SetTextColor(LCD_COLOR_CYAN);
				BSP_LCD_DisplayStringAt(140,80,(uint8_t*)buf,RIGHT_MODE);
				BSP_LCD_SetTextColor(LCD_COLOR_BLACK);
				BSP_LCD_DrawLine(220,SettingUpperTrigger-1,238,SettingUpperTrigger-1);
				BSP_LCD_SetTextColor(LCD_COLOR_RED);
				BSP_LCD_DrawLine(220,SettingUpperTrigger,238,SettingUpperTrigger);
			}
		}

		//upper trigger -
		if (TS_State.TouchDetected==1 && TS_State.X>178 && TS_State.X<198 && TS_State.Y>80 && TS_State.Y<100) {
			if (SettingUpperTrigger>30){
				SettingUpperTrigger--;
				sprintf(buf,"   %d",SettingUpperTrigger);
				BSP_LCD_SetTextColor(LCD_COLOR_CYAN);
				BSP_LCD_DisplayStringAt(140,80,(uint8_t*)buf,RIGHT_MODE);
				BSP_LCD_SetTextColor(LCD_COLOR_BLACK);
				BSP_LCD_DrawLine(220,SettingUpperTrigger+1,238,SettingUpperTrigger+1);
				BSP_LCD_SetTextColor(LCD_COLOR_RED);
				BSP_LCD_DrawLine(220,SettingUpperTrigger,238,SettingUpperTrigger);
			}
		}

		//lower trigger +
		if (TS_State.TouchDetected==1 && TS_State.X>148 && TS_State.X<168 && TS_State.Y>110 && TS_State.Y<130) {
			if (SettingLowerTrigger<290){
				SettingLowerTrigger++;
				sprintf(buf,"   %d",SettingLowerTrigger);
				BSP_LCD_SetTextColor(LCD_COLOR_CYAN);
				BSP_LCD_DisplayStringAt(140,110,(uint8_t*)buf,RIGHT_MODE);
				BSP_LCD_SetTextColor(LCD_COLOR_BLACK);
				BSP_LCD_DrawLine(220,SettingLowerTrigger-1,238,SettingLowerTrigger-1);
				BSP_LCD_SetTextColor(LCD_COLOR_CYAN);
				BSP_LCD_DrawLine(220,SettingLowerTrigger,238,SettingLowerTrigger);
			}
		}

		//lower trigger -
		if (TS_State.TouchDetected==1 && TS_State.X>178 && TS_State.X<198 && TS_State.Y>110 && TS_State.Y<130) {
			if (SettingLowerTrigger>SettingUpperTrigger+20){
				SettingLowerTrigger--;
				sprintf(buf,"   %d",SettingLowerTrigger);
				BSP_LCD_SetTextColor(LCD_COLOR_CYAN);
				BSP_LCD_DisplayStringAt(140,110,(uint8_t*)buf,RIGHT_MODE);
				BSP_LCD_SetTextColor(LCD_COLOR_BLACK);
				BSP_LCD_DrawLine(220,SettingLowerTrigger+1,238,SettingLowerTrigger+1);
				BSP_LCD_SetTextColor(LCD_COLOR_CYAN);
				BSP_LCD_DrawLine(220,SettingLowerTrigger,238,SettingLowerTrigger);
			}
		}

		//gyro button
		if (TS_State.TouchDetected==1 && TS_State.X>30 && TS_State.X<110 && TS_State.Y>150 && TS_State.Y<175) {
			if (controlType==1){
				controlType=0;
				BSP_LCD_SetTextColor(LCD_COLOR_RED);
				BSP_LCD_FillRect(31,151,79,24);
				BSP_LCD_SetTextColor(LCD_COLOR_BLACK);
				BSP_LCD_FillRect(131,151,79,24);
				BSP_LCD_SetTextColor(LCD_COLOR_YELLOW);
				BSP_LCD_SetFont(&Font20);
				BSP_LCD_DisplayStringAt(153,153,(uint8_t*)"TS",LEFT_MODE);
				BSP_LCD_SetBackColor(LCD_COLOR_RED);
				BSP_LCD_DisplayStringAt(43,153,(uint8_t*)"Gyro",LEFT_MODE);
				BSP_LCD_SetBackColor(LCD_COLOR_BLACK);
				angleX=0;
				angleY=0;
				angleZ=0;
			}
		}

		//touchscreen button
		if (TS_State.TouchDetected==1 && TS_State.X>130 && TS_State.X<210 && TS_State.Y>150 && TS_State.Y<175) {
			if (controlType==0){
				controlType=1;
				BSP_LCD_SetTextColor(LCD_COLOR_RED);
				BSP_LCD_FillRect(131,151,79,24);
				BSP_LCD_SetTextColor(LCD_COLOR_BLACK);
				BSP_LCD_FillRect(31,151,79,24);
				BSP_LCD_SetTextColor(LCD_COLOR_YELLOW);
				BSP_LCD_SetFont(&Font20);
				BSP_LCD_DisplayStringAt(43,153,(uint8_t*)"Gyro",LEFT_MODE);
				BSP_LCD_SetBackColor(LCD_COLOR_RED);
				BSP_LCD_DisplayStringAt(153,153,(uint8_t*)"TS",LEFT_MODE);
				BSP_LCD_SetBackColor(LCD_COLOR_BLACK);
			}
		}
		osDelay(10);
	}
}

void gameLoop(){
	fullReset();
	//wait for touch
	WaitForPressedState(1);
	for(;;){
		if (mode==1){
			//to be executed after mode switch - redraw everything
			if (switchedMode){
				switchedMode=0;
				BSP_LCD_Clear(LCD_COLOR_BLACK);
				drawMap();
				BSP_LCD_SetFont(&Font12);
				BSP_LCD_SetBackColor(LCD_COLOR_BLACK);
				BSP_LCD_SetTextColor(LCD_COLOR_YELLOW);
				sprintf(text,"Points: %d",points);
				BSP_LCD_DisplayStringAt(10,10,(uint8_t*)text,LEFT_MODE);
				sprintf(text,"Lives: %d",lives);
				BSP_LCD_DisplayStringAt(235,295,(uint8_t*)text,RIGHT_MODE);
				BSP_LCD_FillCircle((playerPosition.X*12+10),(playerPosition.Y*12+36),5);
				BSP_LCD_SetTextColor(LCD_COLOR_CYAN);
				BSP_LCD_FillCircle((ghostPosition.X*12+10),(ghostPosition.Y*12+36),5);
				//wait for touch
				WaitForPressedState(1);
				if (switchedMode) continue;
			}
			if (totalFood==0){
				BSP_LCD_SetTextColor(LCD_COLOR_YELLOW);
				BSP_LCD_DrawRect(39,129,161,61);
				BSP_LCD_SetTextColor(LCD_COLOR_BLUE);
				BSP_LCD_FillRect(40,130,160,60);
				BSP_LCD_SetBackColor(LCD_COLOR_BLUE);
				BSP_LCD_SetTextColor(LCD_COLOR_YELLOW);
				BSP_LCD_SetFont(&Font16);
				BSP_LCD_DisplayStringAt(43,135,(uint8_t*)"Level complete",LEFT_MODE);
				BSP_LCD_SetFont(&Font12);
				BSP_LCD_DisplayStringAt(59,168,(uint8_t*)"Touch to continue",LEFT_MODE);
				WaitForPressedState(1);
				ResetGame();
				switchedMode=1;
			}
			//gameover message
			else if (lives==0){
				BSP_LCD_SetTextColor(LCD_COLOR_YELLOW);
				BSP_LCD_DrawRect(39,129,161,61);
				BSP_LCD_SetTextColor(LCD_COLOR_BLUE);
				BSP_LCD_FillRect(40,130,160,60);
				BSP_LCD_SetBackColor(LCD_COLOR_BLUE);
				BSP_LCD_SetTextColor(LCD_COLOR_YELLOW);
				BSP_LCD_SetFont(&Font20);
				BSP_LCD_DisplayStringAt(60,135,(uint8_t*)"GAME OVER",LEFT_MODE);
				osDelay(50);
			}
			else {
				//if not gameover, continue
				drawMap();
				if (!proceedMovements()){
					//executes if collision was detected
					//minus 1 life
					lives--;

					//wait for touch
					if (lives){
						softResetGame();
						WaitForPressedState(1);
					}
					else{
						BSP_LCD_SetFont(&Font12);
						BSP_LCD_SetBackColor(LCD_COLOR_BLACK);
						BSP_LCD_SetTextColor(LCD_COLOR_YELLOW);
						sprintf(text,"Lives: %d",lives);
						BSP_LCD_DisplayStringAt(235,295,(uint8_t*)text,RIGHT_MODE);
					}
				}
				//update points
				BSP_LCD_SetFont(&Font12);
				BSP_LCD_SetBackColor(LCD_COLOR_BLACK);
				BSP_LCD_SetTextColor(LCD_COLOR_YELLOW);
				sprintf(text,"Points: %d",points);
				BSP_LCD_DisplayStringAt(10,10,(uint8_t*)text,LEFT_MODE);
			}
		}
		else{
			//display pause screen
			//it has no moving or changing objects, so actually need to draw it once
			if (switchedMode){
				//check if pause message needs to be drawn
				switchedMode=0;
				BSP_LCD_Clear(LCD_COLOR_BLACK);
				BSP_LCD_SetTextColor(LCD_COLOR_BLUE);
				BSP_LCD_FillRect(40,130,160,90);
				BSP_LCD_SetTextColor(LCD_COLOR_YELLOW);
				BSP_LCD_SetBackColor(LCD_COLOR_BLUE);
				BSP_LCD_SetFont(&Font20);
				BSP_LCD_DisplayStringAt(75,135,(uint8_t*)"Paused",LEFT_MODE);
				BSP_LCD_DrawRect(70,160,100,20);
				BSP_LCD_SetFont(&Font16);
				BSP_LCD_DisplayStringAt(75,162,(uint8_t*)"Settings",LEFT_MODE);
				BSP_LCD_DrawRect(70,185,100,20);
				BSP_LCD_SetFont(&Font16);
				BSP_LCD_DisplayStringAt(85,187,(uint8_t*)"Editor",LEFT_MODE);
			}

			//if settings button pressed for more than 50 ms
			if (TS_State.TouchDetected==1 && TS_State.X>70 && TS_State.X<170 && TS_State.Y>160 && TS_State.Y<180){
				uint16_t TimeStart = HAL_GetTick();
				int check=0;
				while(1){
					osDelay(10);
					if (TS_State.TouchDetected==0){
						if (HAL_GetTick()-TimeStart>50) {check=1; break;}
					}
				}
				if (check) manageSettings();
			}

			//if settings button pressed for more than 50 ms
			if (TS_State.TouchDetected==1 && TS_State.X>70 && TS_State.X<170 && TS_State.Y>185 && TS_State.Y<205){
				uint16_t TimeStart = HAL_GetTick();
				int check=0;
				while(1){
					osDelay(10);
					if (TS_State.TouchDetected==0){
						if (HAL_GetTick()-TimeStart>50) {check=1; break;}
					}
				}
				if (check) mapEditor();
			}
			osDelay(10);
		}
	}
}

//user button press handler
void HAL_GPIO_EXTI_Callback(uint16_t GPIO_Pin)
{
  if (GPIO_Pin == GPIO_PIN_0){
		mode=1-mode;
		switchedMode=1;
	}
}

void EXTI0_IRQHandler(void){
	HAL_GPIO_EXTI_IRQHandler(GPIO_PIN_0);
}

/************************ (C) COPYRIGHT STMicroelectronics *****END OF FILE****/
